AUTOSAR XML (schema 4-2-2)
package /STELLANTIS/EPT/COMSWCs
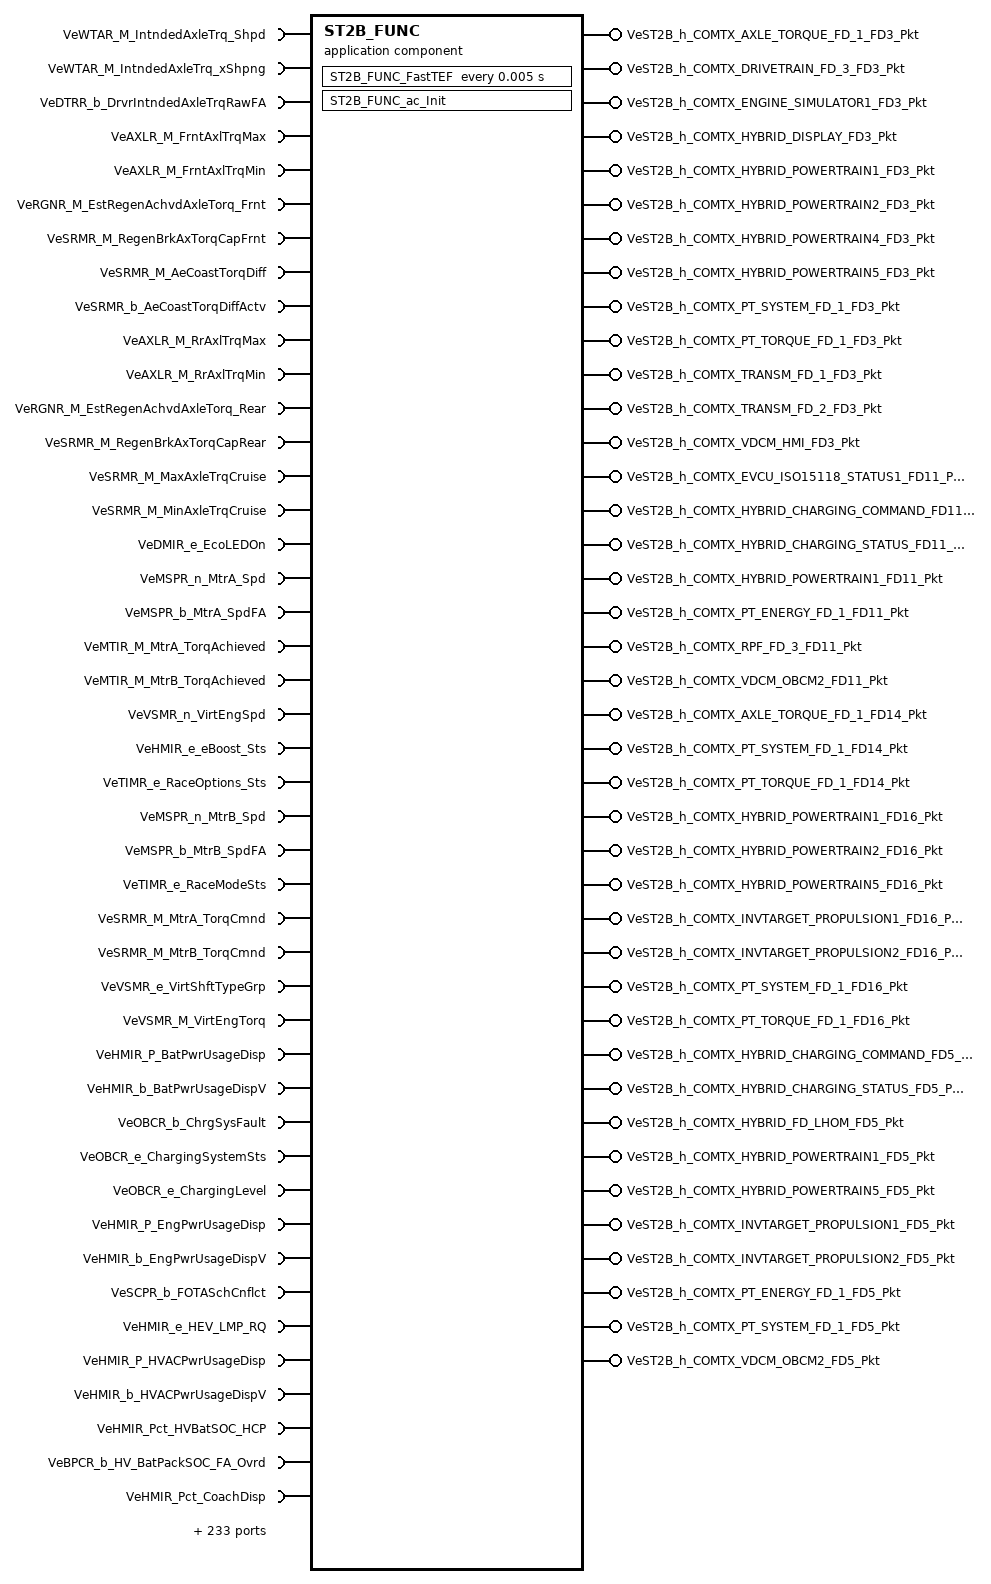
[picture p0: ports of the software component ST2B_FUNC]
  application sw component type ST2B_FUNC
    282 x require port:
      VeWTAR_M_IntndedAxleTrq_Shpd: nonqueued-receiver-com-spec{data-element=Value, init-value=0}, required-interface=VeWTAR_M_IntndedAxleTrq_Shpd
      VeWTAR_M_IntndedAxleTrq_xShpng: nonqueued-receiver-com-spec{data-element=Value, init-value=0}, required-interface=VeWTAR_M_IntndedAxleTrq_xShpng
      VeDTRR_b_DrvrIntndedAxleTrqRawFA: nonqueued-receiver-com-spec{data-element=Value, init-value=0}, required-interface=VeDTRR_b_DrvrIntndedAxleTrqRawFA
      VeAXLR_M_FrntAxlTrqMax: nonqueued-receiver-com-spec{data-element=Value, init-value=0}, required-interface=VeAXLR_M_FrntAxlTrqMax
      VeAXLR_M_FrntAxlTrqMin: nonqueued-receiver-com-spec{data-element=Value, init-value=0}, required-interface=VeAXLR_M_FrntAxlTrqMin
      VeRGNR_M_EstRegenAchvdAxleTorq_Frnt: nonqueued-receiver-com-spec{data-element=Value, init-value=0}, required-interface=VeRGNR_M_EstRegenAchvdAxleTorq_Frnt
      VeSRMR_M_RegenBrkAxTorqCapFrnt: nonqueued-receiver-com-spec{data-element=Value, init-value=0}, required-interface=VeSRMR_M_RegenBrkAxTorqCapFrnt
      VeSRMR_M_AeCoastTorqDiff: nonqueued-receiver-com-spec{data-element=Value, init-value=0}, required-interface=VeSRMR_M_AeCoastTorqDiff
      VeSRMR_b_AeCoastTorqDiffActv: nonqueued-receiver-com-spec{data-element=Value, init-value=0}, required-interface=VeSRMR_b_AeCoastTorqDiffActv
      VeAXLR_M_RrAxlTrqMax: nonqueued-receiver-com-spec{data-element=Value, init-value=0}, required-interface=VeAXLR_M_RrAxlTrqMax
      VeAXLR_M_RrAxlTrqMin: nonqueued-receiver-com-spec{data-element=Value, init-value=0}, required-interface=VeAXLR_M_RrAxlTrqMin
      VeRGNR_M_EstRegenAchvdAxleTorq_Rear: nonqueued-receiver-com-spec{data-element=Value, init-value=0}, required-interface=VeRGNR_M_EstRegenAchvdAxleTorq_Rear
      VeSRMR_M_RegenBrkAxTorqCapRear: nonqueued-receiver-com-spec{data-element=Value, init-value=0}, required-interface=VeSRMR_M_RegenBrkAxTorqCapRear
      VeSRMR_M_MaxAxleTrqCruise: nonqueued-receiver-com-spec{data-element=Value, init-value=0}, required-interface=VeSRMR_M_MaxAxleTrqCruise
      VeSRMR_M_MinAxleTrqCruise: nonqueued-receiver-com-spec{data-element=Value, init-value=0}, required-interface=VeSRMR_M_MinAxleTrqCruise
      VeDMIR_e_EcoLEDOn: variation-point={short-label=vpVeDMIR_e_EcoLEDOn, sw-syscond=1}, nonqueued-receiver-com-spec{data-element=Value, init-value=CeDMDR_e_LEDOff}, required-interface=VeDMIR_e_EcoLEDOn
      VeMSPR_n_MtrA_Spd: variation-point={short-label=vpVeMSPR_n_MtrA_Spd, sw-syscond=1}, nonqueued-receiver-com-spec{data-element=Value, init-value=0}, required-interface=VeMSPR_n_MtrA_Spd
      VeMSPR_b_MtrA_SpdFA: variation-point={short-label=vpVeMSPR_b_MtrA_SpdFA, sw-syscond=1}, nonqueued-receiver-com-spec{data-element=Value, init-value=0}, required-interface=VeMSPR_b_MtrA_SpdFA
      VeMTIR_M_MtrA_TorqAchieved: variation-point={short-label=vpVeMTIR_M_MtrA_TorqAchieved, sw-syscond=1}, nonqueued-receiver-com-spec{data-element=Value, init-value=0}, required-interface=VeMTIR_M_MtrA_TorqAchieved
      VeMTIR_M_MtrB_TorqAchieved: variation-point={short-label=vpVeMTIR_M_MtrB_TorqAchieved, sw-syscond=1}, nonqueued-receiver-com-spec{data-element=Value, init-value=0}, required-interface=VeMTIR_M_MtrB_TorqAchieved
      VeVSMR_n_VirtEngSpd: variation-point={short-label=vpVeVSMR_n_VirtEngSpd, sw-syscond=1}, nonqueued-receiver-com-spec{data-element=Value, init-value=0}, required-interface=VeVSMR_n_VirtEngSpd
      VeHMIR_e_eBoost_Sts: variation-point={short-label=vpVeHMIR_e_eBoost_Sts, sw-syscond=1}, nonqueued-receiver-com-spec{data-element=Value, init-value=CeEBMR_e_eBoostOFF}, required-interface=VeHMIR_e_eBoost_Sts
      VeTIMR_e_RaceOptions_Sts: variation-point={short-label=vpVeTIMR_e_RaceOptions_Sts, sw-syscond=1}, nonqueued-receiver-com-spec{data-element=Value, init-value=CeTIMR_e_NoOptionSelected}, required-interface=VeTIMR_e_RaceOptions_Sts
      VeMSPR_n_MtrB_Spd: variation-point={short-label=vpVeMSPR_n_MtrB_Spd, sw-syscond=1}, nonqueued-receiver-com-spec{data-element=Value, init-value=0}, required-interface=VeMSPR_n_MtrB_Spd
      VeMSPR_b_MtrB_SpdFA: variation-point={short-label=vpVeMSPR_b_MtrB_SpdFA, sw-syscond=1}, nonqueued-receiver-com-spec{data-element=Value, init-value=0}, required-interface=VeMSPR_b_MtrB_SpdFA
      VeTIMR_e_RaceModeSts: variation-point={short-label=vpVeTIMR_e_RaceModeSts, sw-syscond=1}, nonqueued-receiver-com-spec{data-element=Value, init-value=CeTIMR_e_RaceMode_Off}, required-interface=VeTIMR_e_RaceModeSts
      VeSRMR_M_MtrA_TorqCmnd: nonqueued-receiver-com-spec{data-element=Value, init-value=0}, required-interface=VeSRMR_M_MtrA_TorqCmnd
      VeSRMR_M_MtrB_TorqCmnd: nonqueued-receiver-com-spec{data-element=Value, init-value=0}, required-interface=VeSRMR_M_MtrB_TorqCmnd
      VeVSMR_e_VirtShftTypeGrp: variation-point={short-label=vpVeVSMR_e_VirtShftTypeGrp, sw-syscond=1}, nonqueued-receiver-com-spec{data-element=Value, init-value=CeVSMR_e_VST_NoShift}, required-interface=VeVSMR_e_VirtShftTypeGrp
      VeVSMR_M_VirtEngTorq: variation-point={short-label=vpVeVSMR_M_VirtEngTorq, sw-syscond=1}, nonqueued-receiver-com-spec{data-element=Value, init-value=0}, required-interface=VeVSMR_M_VirtEngTorq
      VeHMIR_P_BatPwrUsageDisp: nonqueued-receiver-com-spec{data-element=Value, init-value=0}, required-interface=VeHMIR_P_BatPwrUsageDisp
      VeHMIR_b_BatPwrUsageDispV: nonqueued-receiver-com-spec{data-element=Value, init-value=0}, required-interface=VeHMIR_b_BatPwrUsageDispV
      VeOBCR_b_ChrgSysFault: nonqueued-receiver-com-spec{data-element=Value, init-value=0}, required-interface=VeOBCR_b_ChrgSysFault
      VeOBCR_e_ChargingSystemSts: nonqueued-receiver-com-spec{data-element=Value, init-value=CeOBCR_e_NotCharging}, required-interface=VeOBCR_e_ChargingSystemSts
      VeOBCR_e_ChargingLevel: nonqueued-receiver-com-spec{data-element=Value, init-value=CeOBCR_e_ChargingLvlDefault}, required-interface=VeOBCR_e_ChargingLevel
      VeHMIR_P_EngPwrUsageDisp: nonqueued-receiver-com-spec{data-element=Value, init-value=0}, required-interface=VeHMIR_P_EngPwrUsageDisp
      VeHMIR_b_EngPwrUsageDispV: nonqueued-receiver-com-spec{data-element=Value, init-value=0}, required-interface=VeHMIR_b_EngPwrUsageDispV
      VeSCPR_b_FOTASchCnflct: nonqueued-receiver-com-spec{data-element=Value, init-value=0}, required-interface=VeSCPR_b_FOTASchCnflct
      VeHMIR_e_HEV_LMP_RQ: nonqueued-receiver-com-spec{data-element=Value, init-value=CeHMIR_e_HEV_LMP_OFF}, required-interface=VeHMIR_e_HEV_LMP_RQ
      VeHMIR_P_HVACPwrUsageDisp: nonqueued-receiver-com-spec{data-element=Value, init-value=0}, required-interface=VeHMIR_P_HVACPwrUsageDisp
      VeHMIR_b_HVACPwrUsageDispV: nonqueued-receiver-com-spec{data-element=Value, init-value=0}, required-interface=VeHMIR_b_HVACPwrUsageDispV
      VeHMIR_Pct_HVBatSOC_HCP: nonqueued-receiver-com-spec{data-element=Value, init-value=0}, required-interface=VeHMIR_Pct_HVBatSOC_HCP
      VeBPCR_b_HV_BatPackSOC_FA_Ovrd: nonqueued-receiver-com-spec{data-element=Value, init-value=0}, required-interface=VeBPCR_b_HV_BatPackSOC_FA_Ovrd
      VeHMIR_Pct_CoachDisp: nonqueued-receiver-com-spec{data-element=Value, init-value=0}, required-interface=VeHMIR_Pct_CoachDisp
      VeHMIR_b_CoachDispV: nonqueued-receiver-com-spec{data-element=Value, init-value=0}, required-interface=VeHMIR_b_CoachDispV
      VeHMIR_Pct_OutputPwrDisp: nonqueued-receiver-com-spec{data-element=Value, init-value=0}, required-interface=VeHMIR_Pct_OutputPwrDisp
      VeHMIR_b_OutputPwrDispV: nonqueued-receiver-com-spec{data-element=Value, init-value=0}, required-interface=VeHMIR_b_OutputPwrDispV
      VeOBCR_t_EstTimeofChrg_Lv1: nonqueued-receiver-com-spec{data-element=Value, init-value=0}, required-interface=VeOBCR_t_EstTimeofChrg_Lv1
      VeOBCR_t_EstTimeofChrg_Lv2: nonqueued-receiver-com-spec{data-element=Value, init-value=0}, required-interface=VeOBCR_t_EstTimeofChrg_Lv2
      VeDTRR_e_OPD_HMI: nonqueued-receiver-com-spec{data-element=Value, init-value=CeDTRR_e_Available}, required-interface=VeDTRR_e_OPD_HMI
      VeHMIR_b_Popup_Msg1: variation-point={short-label=vpVeHMIR_b_Popup_Msg1, sw-syscond=1}, nonqueued-receiver-com-spec{data-element=Value, init-value=0}, required-interface=VeHMIR_b_Popup_Msg1
      VeHMIR_b_Popup_Msg10: nonqueued-receiver-com-spec{data-element=Value, init-value=0}, required-interface=VeHMIR_b_Popup_Msg10
      VeHMIR_b_Popup_Msg11: nonqueued-receiver-com-spec{data-element=Value, init-value=0}, required-interface=VeHMIR_b_Popup_Msg11
      VeHMIR_b_Popup_Msg{2..7}: nonqueued-receiver-com-spec{data-element=Value, init-value=0}, required-interface=VeHMIR_b_Popup_Msg{2..7}
      VeSRMR_b_Popup_Msg9: nonqueued-receiver-com-spec{data-element=Value, init-value=0}, required-interface=VeSRMR_b_Popup_Msg9
      VeTIMR_e_RacePrep: variation-point={short-label=vpVeTIMR_e_RacePrep, sw-syscond=1}, nonqueued-receiver-com-spec{data-element=Value, init-value=CeTIMR_e_RacePrep_Off}, required-interface=VeTIMR_e_RacePrep
      VeTAIR_p_HghRfrgtPres: nonqueued-receiver-com-spec{data-element=Value, init-value=0}, required-interface=VeTAIR_p_HghRfrgtPres
      VeTAIR_b_HghRfrgtPres_FA: nonqueued-receiver-com-spec{data-element=Value, init-value=0}, required-interface=VeTAIR_b_HghRfrgtPres_FA
      VeDMIR_e_TellTaleInfo: nonqueued-receiver-com-spec{data-element=Value, init-value=CeDMIR_e_InfoLevel1}, required-interface=VeDMIR_e_TellTaleInfo
      VeHMIR_e_DriveMdstat: nonqueued-receiver-com-spec{data-element=Value, init-value=0}, required-interface=VeHMIR_e_DriveMdstat
      VeHMIR_e_DriveMdstat_PopUpRqst: nonqueued-receiver-com-spec{data-element=Value, init-value=CeDMIR_e_NoDrvMdSt}, required-interface=VeHMIR_e_DriveMdstat_PopUpRqst
      VeHMIR_e_eBoost_Warn: variation-point={short-label=vpVeHMIR_e_eBoost_Warn, sw-syscond=1}, nonqueued-receiver-com-spec{data-element=Value, init-value=CeEBMR_e_DeactivatedESCOff}, required-interface=VeHMIR_e_eBoost_Warn
      VeHMIR_b_DriveReady: nonqueued-receiver-com-spec{data-element=Value, init-value=0}, required-interface=VeHMIR_b_DriveReady
      VeICSR_b_AdvancePrepForIdle: nonqueued-receiver-com-spec{data-element=Value, init-value=0}, required-interface=VeICSR_b_AdvancePrepForIdle
      VeHADR_b_EngActDmpgDsblReq: nonqueued-receiver-com-spec{data-element=Value, init-value=0}, required-interface=VeHADR_b_EngActDmpgDsblReq
      VeTRAR_e_EngCntrlMode: nonqueued-receiver-com-spec{data-element=Value, init-value=CeTRAR_e_TorqueMode}, required-interface=VeTRAR_e_EngCntrlMode
      VeTRAR_M_EngReserveTrqCmnd: nonqueued-receiver-com-spec{data-element=Value, init-value=0}, required-interface=VeTRAR_M_EngReserveTrqCmnd
      VeESSR_b_EngOffAllwdECM: nonqueued-receiver-com-spec{data-element=Value, init-value=0}, required-interface=VeESSR_b_EngOffAllwdECM
      VeGENR_b_HybGenSPDtyCycPtOverAct: nonqueued-receiver-com-spec{data-element=Value, init-value=0}, required-interface=VeGENR_b_HybGenSPDtyCycPtOverAct
      VeESSR_e_EngStrtStpMd: nonqueued-receiver-com-spec{data-element=Value, init-value=CeESSR_e_Stop}, required-interface=VeESSR_e_EngStrtStpMd
      VeTRAR_M_EngTorqCmndImmed: nonqueued-receiver-com-spec{data-element=Value, init-value=0}, required-interface=VeTRAR_M_EngTorqCmndImmed
      VeTRAR_M_HybCmndEngTorqPrdtd: nonqueued-receiver-com-spec{data-element=Value, init-value=0}, required-interface=VeTRAR_M_HybCmndEngTorqPrdtd
      VeTRAR_e_HybCmndEngTorqRespTyp: nonqueued-receiver-com-spec{data-element=Value, init-value=CeTRAR_e_Inactive}, required-interface=VeTRAR_e_HybCmndEngTorqRespTyp
      VeSTRR_b_HybCrnkAbrtd: nonqueued-receiver-com-spec{data-element=Value, init-value=0}, required-interface=VeSTRR_b_HybCrnkAbrtd
      VeTRAR_b_EngDFCOReq: nonqueued-receiver-com-spec{data-element=Value, init-value=0}, required-interface=VeTRAR_b_EngDFCOReq
      VeSRAR_b_CAN_HybFeedback_ECM: nonqueued-receiver-com-spec{data-element=Value, init-value=0}, required-interface=VeSRAR_b_CAN_HybFeedback_ECM
      VeHSER_e_RngStOnCAN: nonqueued-receiver-com-spec{data-element=Value, init-value=CeHSER_e_Init}, required-interface=VeHSER_e_RngStOnCAN
      VeSRAR_b_HCP_Remedial_Stop: variation-point={short-label=vpVeSRAR_b_HCP_Remedial_Stop, sw-syscond=1}, nonqueued-receiver-com-spec{data-element=Value, init-value=0}, required-interface=VeSRAR_b_HCP_Remedial_Stop
      VeTISR_n_InputSpeedRaw: nonqueued-receiver-com-spec{data-element=Value, init-value=0}, required-interface=VeTISR_n_InputSpeedRaw
      VeTISR_b_InputSpeedFA: nonqueued-receiver-com-spec{data-element=Value, init-value=0}, required-interface=VeTISR_b_InputSpeedFA
      VeGENR_b_LowVoltSysFldToECM: nonqueued-receiver-com-spec{data-element=Value, init-value=0}, required-interface=VeGENR_b_LowVoltSysFldToECM
      VeHPMR_b_PropSysActv: nonqueued-receiver-com-spec{data-element=Value, init-value=0}, required-interface=VeHPMR_b_PropSysActv
      VeHSER_n_InputSpeedProfile: nonqueued-receiver-com-spec{data-element=Value, init-value=0}, required-interface=VeHSER_n_InputSpeedProfile
      VeOHSR_n_IdleSpeed_Target: nonqueued-receiver-com-spec{data-element=Value, init-value=0}, required-interface=VeOHSR_n_IdleSpeed_Target
      VeTRNR_b_PwrTrnIdlSpdActvSts: nonqueued-receiver-com-spec{data-element=Value, init-value=0}, required-interface=VeTRNR_b_PwrTrnIdlSpdActvSts
      VeTMDR_e_Arb_TrrnMd: variation-point={short-label=vpVeTMDR_e_Arb_TrrnMd, sw-syscond=1}, nonqueued-receiver-com-spec{data-element=Value, init-value=0}, required-interface=VeTMDR_e_Arb_TrrnMd
      VeBACR_r_ElecPwrTorq_PedalFact: nonqueued-receiver-com-spec{data-element=Value, init-value=0}, required-interface=VeBACR_r_ElecPwrTorq_PedalFact
      VeSRAR_n_HCPMaxEngRPM: nonqueued-receiver-com-spec{data-element=Value, init-value=0}, required-interface=VeSRAR_n_HCPMaxEngRPM
      VeESSR_b_HCP_StopStart_Fault: nonqueued-receiver-com-spec{data-element=Value, init-value=0}, required-interface=VeESSR_b_HCP_StopStart_Fault
      VeSRAR_b_HybPwrtrnRdcdPerfCmnd: nonqueued-receiver-com-spec{data-element=Value, init-value=0}, required-interface=VeSRAR_b_HybPwrtrnRdcdPerfCmnd
      VeCOMR_b_Random3: nonqueued-receiver-com-spec{data-element=Value, init-value=0}, required-interface=VeCOMR_b_Random3
      VeTAIR_Pct_AGS2_CurrPos: nonqueued-receiver-com-spec{data-element=Value, init-value=0}, required-interface=VeTAIR_Pct_AGS2_CurrPos
      VeTAIR_b_AGS2_CurrPosFA: nonqueued-receiver-com-spec{data-element=Value, init-value=0}, required-interface=VeTAIR_b_AGS2_CurrPosFA
      VeTAIR_Pct_AGS_CurrPos: nonqueued-receiver-com-spec{data-element=Value, init-value=0}, required-interface=VeTAIR_Pct_AGS_CurrPos
      VeTAIR_b_AGS_CurrPosFA: nonqueued-receiver-com-spec{data-element=Value, init-value=0}, required-interface=VeTAIR_b_AGS_CurrPosFA
      VeHMIR_b_HEV_EVT_MD: nonqueued-receiver-com-spec{data-element=Value, init-value=0}, required-interface=VeHMIR_b_HEV_EVT_MD
      VeTIMR_e_LaunchIntensity: variation-point={short-label=vpVeTIMR_e_LaunchIntensity, sw-syscond=1}, nonqueued-receiver-com-spec{data-element=Value, init-value=CeTIMR_e_Max}, required-interface=VeTIMR_e_LaunchIntensity
      VeHMIR_P_MtrAPwrUsageDisp: variation-point={short-label=vpVeHMIR_P_MtrAPwrUsageDisp, sw-syscond=1}, nonqueued-receiver-com-spec{data-element=Value, init-value=0}, required-interface=VeHMIR_P_MtrAPwrUsageDisp
      VeHMIR_P_MtrAPwrUsageDispV: variation-point={short-label=vpVeHMIR_P_MtrAPwrUsageDispV, sw-syscond=1}, nonqueued-receiver-com-spec{data-element=Value, init-value=0}, required-interface=VeHMIR_P_MtrAPwrUsageDispV
      VeHMIR_P_MtrBPwrUsageDisp: nonqueued-receiver-com-spec{data-element=Value, init-value=0}, required-interface=VeHMIR_P_MtrBPwrUsageDisp
      VeHMIR_P_MtrBPwrUsageDispV: nonqueued-receiver-com-spec{data-element=Value, init-value=0}, required-interface=VeHMIR_P_MtrBPwrUsageDispV
      VeHMIR_P_MtrPwrUsageDisp: nonqueued-receiver-com-spec{data-element=Value, init-value=0}, required-interface=VeHMIR_P_MtrPwrUsageDisp
      VeHMIR_b_MtrPwrUsageDispV: nonqueued-receiver-com-spec{data-element=Value, init-value=0}, required-interface=VeHMIR_b_MtrPwrUsageDispV
      VeSRMR_e_AHH_ApplyRelease_Req: nonqueued-receiver-com-spec{data-element=Value, init-value=0}, required-interface=VeSRMR_e_AHH_ApplyRelease_Req
      VeSRMR_b_AHH_ModifyAccel_Req: nonqueued-receiver-com-spec{data-element=Value, init-value=0}, required-interface=VeSRMR_b_AHH_ModifyAccel_Req
      VeTRGR_e_AutoPosCorrMdReq: nonqueued-receiver-com-spec{data-element=Value, init-value=CeTRGR_e_AutoPosCorrMd_Off}, required-interface=VeTRGR_e_AutoPosCorrMdReq
      VeADCR_e_AWDSysStat: nonqueued-receiver-com-spec{data-element=Value, init-value=CeADCR_e_TwoWheelDrive}, required-interface=VeADCR_e_AWDSysStat
      VeGENR_b_SrvcBattReChrgFlSts: nonqueued-receiver-com-spec{data-element=Value, init-value=0}, required-interface=VeGENR_b_SrvcBattReChrgFlSts
      VePLTR_pmbar_AmbientAirPrs: nonqueued-receiver-com-spec{data-element=Value, init-value=0}, required-interface=VePLTR_pmbar_AmbientAirPrs
      VeCCTR_v_CcCntrlSpd_Cluster_KPH: nonqueued-receiver-com-spec{data-element=Value, init-value=0}, required-interface=VeCCTR_v_CcCntrlSpd_Cluster_KPH
      VeCCTR_v_CcCntrlSpd_Cluster_MPH: nonqueued-receiver-com-spec{data-element=Value, init-value=0}, required-interface=VeCCTR_v_CcCntrlSpd_Cluster_MPH
      VeTRGR_b_CrankEnabled: nonqueued-receiver-com-spec{data-element=Value, init-value=0}, required-interface=VeTRGR_b_CrankEnabled
      VeCCTR_b_CcLampSts: nonqueued-receiver-com-spec{data-element=Value, init-value=0}, required-interface=VeCCTR_b_CcLampSts
      VeCCTR_b_CcEngaged: nonqueued-receiver-com-spec{data-element=Value, init-value=0}, required-interface=VeCCTR_b_CcEngaged
      VeTIMR_e_CustomDrvMdSts: nonqueued-receiver-com-spec{data-element=Value, init-value=CeTMDR_e_NotDefine}, required-interface=VeTIMR_e_CustomDrvMdSts
      VeHMIR_b_DrvAwayAlt: nonqueued-receiver-com-spec{data-element=Value, init-value=0}, required-interface=VeHMIR_b_DrvAwayAlt
      VeHMIR_b_DrvAwayIn: nonqueued-receiver-com-spec{data-element=Value, init-value=0}, required-interface=VeHMIR_b_DrvAwayIn
      VeTRGR_b_AutoPark_DAI: nonqueued-receiver-com-spec{data-element=Value, init-value=0}, required-interface=VeTRGR_b_AutoPark_DAI
      VeSRMR_b_Lv2AccelPdlPosFlt: nonqueued-receiver-com-spec{data-element=Value, init-value=0}, required-interface=VeSRMR_b_Lv2AccelPdlPosFlt
      VeDTRR_Pct_AccelPdlVirtActPosn: nonqueued-receiver-com-spec{data-element=Value, init-value=0}, required-interface=VeDTRR_Pct_AccelPdlVirtActPosn
      VeTRGR_e_CurrentGrForDisp: nonqueued-receiver-com-spec{data-element=Value, init-value=0}, required-interface=VeTRGR_e_CurrentGrForDisp
      VeTRGR_e_CurrentGear: nonqueued-receiver-com-spec{data-element=Value, init-value=0}, required-interface=VeTRGR_e_CurrentGear
      VeTRGR_b_GearIndicationSts: nonqueued-receiver-com-spec{data-element=Value, init-value=0}, required-interface=VeTRGR_b_GearIndicationSts
      VeASLR_b_ISASts: nonqueued-receiver-com-spec{data-element=Value, init-value=0}, required-interface=VeASLR_b_ISASts
      VeDMIR_e_PaddleModeSts: nonqueued-receiver-com-spec{data-element=Value, init-value=CeDMIR_e_None}, required-interface=VeDMIR_e_PaddleModeSts
      VeTRGR_b_ParkingFailSts: nonqueued-receiver-com-spec{data-element=Value, init-value=0}, required-interface=VeTRGR_b_ParkingFailSts
      VeTRGR_b_ParkingSts: nonqueued-receiver-com-spec{data-element=Value, init-value=0}, required-interface=VeTRGR_b_ParkingSts
      VeSRMR_Pct_Lv2AccelPdlPos: nonqueued-receiver-com-spec{data-element=Value, init-value=0}, required-interface=VeSRMR_Pct_Lv2AccelPdlPos
      VeTRGR_b_ADAS_Allowed: nonqueued-receiver-com-spec{data-element=Value, init-value=0}, required-interface=VeTRGR_b_ADAS_Allowed
      VeTRGR_b_R_Shift_Block: nonqueued-receiver-com-spec{data-element=Value, init-value=0}, required-interface=VeTRGR_b_R_Shift_Block
      VeAPSR_U_RawPVS1: nonqueued-receiver-com-spec{data-element=Value, init-value=0}, required-interface=VeAPSR_U_RawPVS1
      VeAPSR_U_RawPVS2: nonqueued-receiver-com-spec{data-element=Value, init-value=0}, required-interface=VeAPSR_U_RawPVS2
      VeTRGR_e_SecureIdle_HMI: nonqueued-receiver-com-spec{data-element=Value, init-value=CeTRGR_e_SecureIdleHMI_Default}, required-interface=VeTRGR_e_SecureIdle_HMI
      VeTRGR_e_SecureIdleSts: nonqueued-receiver-com-spec{data-element=Value, init-value=0}, required-interface=VeTRGR_e_SecureIdleSts
      VeTIMR_b_Selector_Sys_Fail_Sts: nonqueued-receiver-com-spec{data-element=Value, init-value=0}, required-interface=VeTIMR_b_Selector_Sys_Fail_Sts
      VeTRGR_b_ShifterLocked: nonqueued-receiver-com-spec{data-element=Value, init-value=0}, required-interface=VeTRGR_b_ShifterLocked
      VeSRMR_e_PRNDLReq: nonqueued-receiver-com-spec{data-element=Value, init-value=0}, required-interface=VeSRMR_e_PRNDLReq
      VeASLR_e_SpdLmtSts: nonqueued-receiver-com-spec{data-element=Value, init-value=0}, required-interface=VeASLR_e_SpdLmtSts
      VeTRGR_e_TargetGear: nonqueued-receiver-com-spec{data-element=Value, init-value=0}, required-interface=VeTRGR_e_TargetGear
      VeHMIR_e_TerrainModeDesiredStat: nonqueued-receiver-com-spec{data-element=Value, init-value=CeHMIR_e_Auto}, required-interface=VeHMIR_e_TerrainModeDesiredStat
      VeTIMR_e_CustomScreenRqst: variation-point={short-label=vpVeTIMR_e_CustomScreenRqst, sw-syscond=1}, nonqueued-receiver-com-spec{data-element=Value, init-value=CeTIMR_e_NotActivated}, required-interface=VeTIMR_e_CustomScreenRqst
      VeHMIR_e_TerrainModeStat: nonqueued-receiver-com-spec{data-element=Value, init-value=CeHMIR_e_AutoStat}, required-interface=VeHMIR_e_TerrainModeStat
      VeHMIR_e_TerrainHMIRq: nonqueued-receiver-com-spec{data-element=Value, init-value=CeHMIR_e_No_Request}, required-interface=VeHMIR_e_TerrainHMIRq
      VeTRGR_b_TransmissionFailSts: nonqueued-receiver-com-spec{data-element=Value, init-value=0}, required-interface=VeTRGR_b_TransmissionFailSts
      VeHMIR_e_TransWarn2: nonqueued-receiver-com-spec{data-element=Value, init-value=CeHMIR_e_Warn2_None}, required-interface=VeHMIR_e_TransWarn2
      VeDMDR_e_TurtleMdSts: nonqueued-receiver-com-spec{data-element=Value, init-value=CeDMDR_e_No_Turtle_Mode}, required-interface=VeDMDR_e_TurtleMdSts
      VeASLR_e_DrvMdOvrrdKickdownSt: nonqueued-receiver-com-spec{data-element=Value, init-value=0}, required-interface=VeASLR_e_DrvMdOvrrdKickdownSt
      VeSRMR_e_EPB_Hold_Req: nonqueued-receiver-com-spec{data-element=Value, init-value=0}, required-interface=VeSRMR_e_EPB_Hold_Req
      VeADCR_i_WEDAxleStat_CAN: nonqueued-receiver-com-spec{data-element=Value, init-value=0}, required-interface=VeADCR_i_WEDAxleStat_CAN
      VeAPSR_b_Lv1PvBrkActive: nonqueued-receiver-com-spec{data-element=Value, init-value=0}, required-interface=VeAPSR_b_Lv1PvBrkActive
      VeDTRR_b_EngTrqEnblRqDAS: nonqueued-receiver-com-spec{data-element=Value, init-value=0}, required-interface=VeDTRR_b_EngTrqEnblRqDAS
      VeDTRR_b_PtcCcDriverOverride: nonqueued-receiver-com-spec{data-element=Value, init-value=0}, required-interface=VeDTRR_b_PtcCcDriverOverride
      VeSCCR_b_ESCTrqEnblRq_Allowed: nonqueued-receiver-com-spec{data-element=Value, init-value=0}, required-interface=VeSCCR_b_ESCTrqEnblRq_Allowed
      VeSRMR_M_SplitFrntTrqReq: nonqueued-receiver-com-spec{data-element=Value, init-value=0}, required-interface=VeSRMR_M_SplitFrntTrqReq
      VeAXLR_M_SplitFrntTrqReq: nonqueued-receiver-com-spec{data-element=Value, init-value=0}, required-interface=VeAXLR_M_SplitFrntTrqReq
      VeSRMR_M_SplitRearTrqReq: nonqueued-receiver-com-spec{data-element=Value, init-value=0}, required-interface=VeSRMR_M_SplitRearTrqReq
      VeAXLR_M_SplitRrAxlTrqReq: nonqueued-receiver-com-spec{data-element=Value, init-value=0}, required-interface=VeAXLR_M_SplitRrAxlTrqReq
      VeTTQR_M_LoadFrontOptExp: variation-point={short-label=vpVeTTQR_M_LoadFrontOptExp, sw-syscond=1}, nonqueued-receiver-com-spec{data-element=Value, init-value=0}, required-interface=VeTTQR_M_LoadFrontOptExp
      VeTTQR_M_LoadTorqFront_Max: nonqueued-receiver-com-spec{data-element=Value, init-value=0}, required-interface=VeTTQR_M_LoadTorqFront_Max
      VeTTQR_M_SumTrqMinPwrTrn: nonqueued-receiver-com-spec{data-element=Value, init-value=0}, required-interface=VeTTQR_M_SumTrqMinPwrTrn
      VeTTQR_M_SumTrqStatic: nonqueued-receiver-com-spec{data-element=Value, init-value=0}, required-interface=VeTTQR_M_SumTrqStatic
      VeSRMR_M_ActualAxleTrq: nonqueued-receiver-com-spec{data-element=Value, init-value=0}, required-interface=VeSRMR_M_ActualAxleTrq
      VeSRMR_b_VehStndStillReq_OPD: nonqueued-receiver-com-spec{data-element=Value, init-value=0}, required-interface=VeSRMR_b_VehStndStillReq_OPD
      VeHMIR_b_ThrmlRnAway_Lmp: nonqueued-receiver-com-spec{data-element=Value, init-value=0}, required-interface=VeHMIR_b_ThrmlRnAway_Lmp
      VeOBCR_t_EstTimeDCFastChrg_80: nonqueued-receiver-com-spec{data-element=Value, init-value=0}, required-interface=VeOBCR_t_EstTimeDCFastChrg_80
      VeOBCR_t_EstTimeDCFastChrg_100: nonqueued-receiver-com-spec{data-element=Value, init-value=0}, required-interface=VeOBCR_t_EstTimeDCFastChrg_100
      VeERER_l_EstRange: nonqueued-receiver-com-spec{data-element=Value, init-value=0}, required-interface=VeERER_l_EstRange
      VeERER_b_EstRange_SNA: nonqueued-receiver-com-spec{data-element=Value, init-value=0}, required-interface=VeERER_b_EstRange_SNA
      VeHMIR_Pct_EstSOCDisplay: nonqueued-receiver-com-spec{data-element=Value, init-value=0}, required-interface=VeHMIR_Pct_EstSOCDisplay
      VeERER_l_EstRange_ChrgStpTime: nonqueued-receiver-com-spec{data-element=Value, init-value=0}, required-interface=VeERER_l_EstRange_ChrgStpTime
      VeHMIR_e_VDCM_PopUpChrgPrtMis: nonqueued-receiver-com-spec{data-element=Value, init-value=CeHMIR_e_Not_Availabl}, required-interface=VeHMIR_e_VDCM_PopUpChrgPrtMis
      VeSSDR_b_DrvNotAllwdTPChckKeepPlugIn: nonqueued-receiver-com-spec{data-element=Value, init-value=0}, required-interface=VeSSDR_b_DrvNotAllwdTPChckKeepPlugIn
      VeOBCR_I_EVMax_I_Limit: nonqueued-receiver-com-spec{data-element=Value, init-value=0}, required-interface=VeOBCR_I_EVMax_I_Limit
      VeOBCR_U_EVMax_V_Limit: nonqueued-receiver-com-spec{data-element=Value, init-value=0}, required-interface=VeOBCR_U_EVMax_V_Limit
      VeOBCR_e_ChargeProgress: nonqueued-receiver-com-spec{data-element=Value, init-value=CeOBCR_e_No_Request}, required-interface=VeOBCR_e_ChargeProgress
      VeOBCR_E_EVEnergyCapacity: nonqueued-receiver-com-spec{data-element=Value, init-value=0}, required-interface=VeOBCR_E_EVEnergyCapacity
      VeOBCR_E_EVEnergyRequest: nonqueued-receiver-com-spec{data-element=Value, init-value=0}, required-interface=VeOBCR_E_EVEnergyRequest
      VeOBCR_e_HCP_EVErrorCode: nonqueued-receiver-com-spec{data-element=Value, init-value=0}, required-interface=VeOBCR_e_HCP_EVErrorCode
      VeOBCR_t_RemTimeToBulkSOC: nonqueued-receiver-com-spec{data-element=Value, init-value=0}, required-interface=VeOBCR_t_RemTimeToBulkSOC
      VeOBCR_t_RemTimeToFullSOC: nonqueued-receiver-com-spec{data-element=Value, init-value=0}, required-interface=VeOBCR_t_RemTimeToFullSOC
      VeOBCR_k_MaxEntriesSASScheduleTuple: nonqueued-receiver-com-spec{data-element=Value, init-value=0}, required-interface=VeOBCR_k_MaxEntriesSASScheduleTuple
      VeOBCR_e_Protocol_Priority{1..3}: nonqueued-receiver-com-spec{data-element=Value, init-value=CeOBCR_e_No_Protocol}, required-interface=VeOBCR_e_Protocol_Priority{1..3}
      VeOBCR_I_MaxAllowableCrntAC: nonqueued-receiver-com-spec{data-element=Value, init-value=0}, required-interface=VeOBCR_I_MaxAllowableCrntAC
      VeOBCR_b_EnblChrg: nonqueued-receiver-com-spec{data-element=Value, init-value=0}, required-interface=VeOBCR_b_EnblChrg
      VeOBCR_I_ChrgCrntReqDelta: nonqueued-receiver-com-spec{data-element=Value, init-value=0}, required-interface=VeOBCR_I_ChrgCrntReqDelta
      VeOBCR_I_MaxAllowableCrntBatt: nonqueued-receiver-com-spec{data-element=Value, init-value=0}, required-interface=VeOBCR_I_MaxAllowableCrntBatt
      VeTHMR_e_HV_Bat_CltLvlLo: nonqueued-receiver-com-spec{data-element=Value, init-value=CeBRDR_e_BatCltLvlNotLo}, required-interface=VeTHMR_e_HV_Bat_CltLvlLo
      VeOBCR_U_MaxAllowableBattVolt: nonqueued-receiver-com-spec{data-element=Value, init-value=0}, required-interface=VeOBCR_U_MaxAllowableBattVolt
      VeOBCR_U_MinAllowableBattVolt: nonqueued-receiver-com-spec{data-element=Value, init-value=0}, required-interface=VeOBCR_U_MinAllowableBattVolt
      VeOBCR_b_CloseS2Cntctr: nonqueued-receiver-com-spec{data-element=Value, init-value=0}, required-interface=VeOBCR_b_CloseS2Cntctr
      VeVTLR_I_MaxCurrAlwd_IDCM: nonqueued-receiver-com-spec{data-element=Value, init-value=0}, required-interface=VeVTLR_I_MaxCurrAlwd_IDCM
      VeOBCR_e_ChrgrTrsfMethodReq: nonqueued-receiver-com-spec{data-element=Value, init-value=CeOBCR_e_Current}, required-interface=VeOBCR_e_ChrgrTrsfMethodReq
      VeOBCR_e_ChrgrModeReq: nonqueued-receiver-com-spec{data-element=Value, init-value=CeOBCR_e_Idle_OBCMdRq}, required-interface=VeOBCR_e_ChrgrModeReq
      VeOBCR_b_HCP_SessionStpCmd: nonqueued-receiver-com-spec{data-element=Value, init-value=0}, required-interface=VeOBCR_b_HCP_SessionStpCmd
      VeOBCR_U_ChrgVltReqDelta: nonqueued-receiver-com-spec{data-element=Value, init-value=0}, required-interface=VeOBCR_U_ChrgVltReqDelta
      VeOBCR_b_ChrgSysFaultBPCM: nonqueued-receiver-com-spec{data-element=Value, init-value=0}, required-interface=VeOBCR_b_ChrgSysFaultBPCM
      VeOBCR_k_ChrgSysFault_Reason: nonqueued-receiver-com-spec{data-element=Value, init-value=0}, required-interface=VeOBCR_k_ChrgSysFault_Reason
      VeOBCR_b_PluggedIn: nonqueued-receiver-com-spec{data-element=Value, init-value=0}, required-interface=VeOBCR_b_PluggedIn
      VeBPCR_I_HV_BatCurr: nonqueued-receiver-com-spec{data-element=Value, init-value=0}, required-interface=VeBPCR_I_HV_BatCurr
      VeBPCR_b_HV_BatCurrFA: nonqueued-receiver-com-spec{data-element=Value, init-value=0}, required-interface=VeBPCR_b_HV_BatCurrFA
      VeBPCR_U_HV_BatVolt: nonqueued-receiver-com-spec{data-element=Value, init-value=0}, required-interface=VeBPCR_U_HV_BatVolt
      VeBPCR_b_HV_BatVoltFA: nonqueued-receiver-com-spec{data-element=Value, init-value=0}, required-interface=VeBPCR_b_HV_BatVoltFA
      VeGENR_e_stModeReq: nonqueued-receiver-com-spec{data-element=Value, init-value=CeGENR_e_Default}, required-interface=VeGENR_e_stModeReq
      VeGENR_I_APMIdcHvSetP: nonqueued-receiver-com-spec{data-element=Value, init-value=0}, required-interface=VeGENR_I_APMIdcHvSetP
      VeGENR_b_APMIdcHvSetPFA: nonqueued-receiver-com-spec{data-element=Value, init-value=0}, required-interface=VeGENR_b_APMIdcHvSetPFA
      VeGENR_I_APM_IdcLvSetP: nonqueued-receiver-com-spec{data-element=Value, init-value=0}, required-interface=VeGENR_I_APM_IdcLvSetP
      VeGENR_U_IBS_BattVoltOut: nonqueued-receiver-com-spec{data-element=Value, init-value=0}, required-interface=VeGENR_U_IBS_BattVoltOut
      VeGENR_U_SetPVoltRq: nonqueued-receiver-com-spec{data-element=Value, init-value=0}, required-interface=VeGENR_U_SetPVoltRq
      VeGENR_b_SetPVoltRqFA: nonqueued-receiver-com-spec{data-element=Value, init-value=0}, required-interface=VeGENR_b_SetPVoltRqFA
      VeOBCR_e_DC_CntctrCmd: nonqueued-receiver-com-spec{data-element=Value, init-value=CeOBCR_e_DCCntctr_Open}, required-interface=VeOBCR_e_DC_CntctrCmd
      VeOBCR_b_DC_Isolation_Cmd: nonqueued-receiver-com-spec{data-element=Value, init-value=0}, required-interface=VeOBCR_b_DC_Isolation_Cmd
      VeHVTR_U_HV_Volt: nonqueued-receiver-com-spec{data-element=Value, init-value=0}, required-interface=VeHVTR_U_HV_Volt
      VeHVTR_b_HV_VoltFA: nonqueued-receiver-com-spec{data-element=Value, init-value=0}, required-interface=VeHVTR_b_HV_VoltFA
      VeSRMR_e_MainHighVltCntctrCmd: nonqueued-receiver-com-spec{data-element=Value, init-value=0}, required-interface=VeSRMR_e_MainHighVltCntctrCmd
      VeOBCR_b_DCChrgInitialization: nonqueued-receiver-com-spec{data-element=Value, init-value=0}, required-interface=VeOBCR_b_DCChrgInitialization
      VeOBCR_e_DC_ChrgTypeCmd: nonqueued-receiver-com-spec{data-element=Value, init-value=CeOBCR_e_DC_ChrgType_Null}, required-interface=VeOBCR_e_DC_ChrgTypeCmd
      VeHPMR_b_EVCURespAuxLoadOff: nonqueued-receiver-com-spec{data-element=Value, init-value=0}, required-interface=VeHPMR_b_EVCURespAuxLoadOff
      VeVTLR_b_ACFreqCmd: nonqueued-receiver-com-spec{data-element=Value, init-value=0}, required-interface=VeVTLR_b_ACFreqCmd
      VeVTLR_I_MaxCurrAlwd_PPIM: nonqueued-receiver-com-spec{data-element=Value, init-value=0}, required-interface=VeVTLR_I_MaxCurrAlwd_PPIM
      VeVTLR_e_PPIM_MdRq: nonqueued-receiver-com-spec{data-element=Value, init-value=CeVTLR_e_Idle}, required-interface=VeVTLR_e_PPIM_MdRq
      VeOBCR_b_CPIM_Error: nonqueued-receiver-com-spec{data-element=Value, init-value=0}, required-interface=VeOBCR_b_CPIM_Error
      VeOBCR_b_CPIM_OT: nonqueued-receiver-com-spec{data-element=Value, init-value=0}, required-interface=VeOBCR_b_CPIM_OT
      VeOBCR_e_HCP_DC_Retry: nonqueued-receiver-com-spec{data-element=Value, init-value=CeOBCR_e_No_Retry_Command}, required-interface=VeOBCR_e_HCP_DC_Retry
      VeOBCR_e_SelectAppProtocol: nonqueued-receiver-com-spec{data-element=Value, init-value=CeOBCR_e_DIN}, required-interface=VeOBCR_e_SelectAppProtocol
      VeOBCR_b_SelectSecProtocol: nonqueued-receiver-com-spec{data-element=Value, init-value=0}, required-interface=VeOBCR_b_SelectSecProtocol
      VeOBCR_Pct_BattFullSOC: nonqueued-receiver-com-spec{data-element=Value, init-value=0}, required-interface=VeOBCR_Pct_BattFullSOC
      VeOBCR_b_BattOverVolt: nonqueued-receiver-com-spec{data-element=Value, init-value=0}, required-interface=VeOBCR_b_BattOverVolt
      VeOBCR_e_BattTemp_OOR: nonqueued-receiver-com-spec{data-element=Value, init-value=CeOBCR_e_BattTempStat_Normal}, required-interface=VeOBCR_e_BattTemp_OOR
      VeOBCR_b_BattUnderVolt: nonqueued-receiver-com-spec{data-element=Value, init-value=0}, required-interface=VeOBCR_b_BattUnderVolt
      VeOBCR_e_CellVolt_OOR: nonqueued-receiver-com-spec{data-element=Value, init-value=CeOBCR_e_CellVoltStat_Normal}, required-interface=VeOBCR_e_CellVolt_OOR
      VeOBCR_e_ChrgCurr_OOR: nonqueued-receiver-com-spec{data-element=Value, init-value=CeOBCR_e_ChrgCurrStat_Normal}, required-interface=VeOBCR_e_ChrgCurr_OOR
      VeOBCR_e_SOC_OOR: nonqueued-receiver-com-spec{data-element=Value, init-value=CeOBCR_e_BattSOCStat_Normal}, required-interface=VeOBCR_e_SOC_OOR
      VeOBCR_b_WeldChkComplete: nonqueued-receiver-com-spec{data-element=Value, init-value=0}, required-interface=VeOBCR_b_WeldChkComplete
      VeSRMR_M_SnsdEng_Flt: nonqueued-receiver-com-spec{data-element=Value, init-value=0}, required-interface=VeSRMR_M_SnsdEng_Flt
      VeSRMR_b_SnsdTi_notVld: nonqueued-receiver-com-spec{data-element=Value, init-value=0}, required-interface=VeSRMR_b_SnsdTi_notVld
      VeHSER_e_RngStToPropulsionMode: nonqueued-receiver-com-spec{data-element=Value, init-value=CeHSER_e_PropModeSNA}, required-interface=VeHSER_e_RngStToPropulsionMode
      VeHTDR_f_MtrA_AEMDFc_Hi: nonqueued-receiver-com-spec{data-element=Value, init-value=0}, required-interface=VeHTDR_f_MtrA_AEMDFc_Hi
      VeHTDR_f_MtrB_AEMDFc_Hi: nonqueued-receiver-com-spec{data-element=Value, init-value=0}, required-interface=VeHTDR_f_MtrB_AEMDFc_Hi
      VeHTDR_f_MtrA_AEMDFc_Lo: nonqueued-receiver-com-spec{data-element=Value, init-value=0}, required-interface=VeHTDR_f_MtrA_AEMDFc_Lo
      VeHTDR_f_MtrB_AEMDFc_Lo: nonqueued-receiver-com-spec{data-element=Value, init-value=0}, required-interface=VeHTDR_f_MtrB_AEMDFc_Lo
      VeHTDR_M_MtrA_AEMDPosTrqOffst: variation-point={short-label=vpVeHTDR_M_MtrA_AEMDPosTrqOffst, sw-syscond=1}, nonqueued-receiver-com-spec{data-element=Value, init-value=0}, required-interface=VeHTDR_M_MtrA_AEMDPosTrqOffst
      VeHTDR_M_MtrB_AEMDPosTrqOffst: nonqueued-receiver-com-spec{data-element=Value, init-value=0}, required-interface=VeHTDR_M_MtrB_AEMDPosTrqOffst
      VeHTDR_M_MtrA_AEMDNegTrqOffst: variation-point={short-label=vpVeHTDR_M_MtrA_AEMDNegTrqOffst, sw-syscond=1}, nonqueued-receiver-com-spec{data-element=Value, init-value=0}, required-interface=VeHTDR_M_MtrA_AEMDNegTrqOffst
      VeHTDR_M_MtrB_AEMDNegTrqOffst: nonqueued-receiver-com-spec{data-element=Value, init-value=0}, required-interface=VeHTDR_M_MtrB_AEMDNegTrqOffst
      VeHTDR_scl_MtrA_AEMDPGainScl: variation-point={short-label=vpVeHTDR_scl_MtrA_AEMDPGainScl, sw-syscond=1}, nonqueued-receiver-com-spec{data-element=Value, init-value=0}, required-interface=VeHTDR_scl_MtrA_AEMDPGainScl
      VeHTDR_scl_MtrB_AEMDPGainScl: nonqueued-receiver-com-spec{data-element=Value, init-value=0}, required-interface=VeHTDR_scl_MtrB_AEMDPGainScl
      VeBPCR_e_HV_BatCntctrStat: nonqueued-receiver-com-spec{data-element=Value, init-value=CeHVTR_e_Open}, required-interface=VeBPCR_e_HV_BatCntctrStat
      VePMDR_e_PowerModeRaw: nonqueued-receiver-com-spec{data-element=Value, init-value=CePMDR_e_PowerMode_Off}, required-interface=VePMDR_e_PowerModeRaw
      VeSRMR_e_MtrA_MdCmnd: nonqueued-receiver-com-spec{data-element=Value, init-value=CeHTDR_e_DsblNoSwitch}, required-interface=VeSRMR_e_MtrA_MdCmnd
      VeSRMR_e_MtrB_MdCmnd: nonqueued-receiver-com-spec{data-element=Value, init-value=CeHTDR_e_DsblNoSwitch}, required-interface=VeSRMR_e_MtrB_MdCmnd
      VeHTDR_b_MtrA_ZeroTrq_Rqst: variation-point={short-label=vpVeHTDR_b_MtrA_ZeroTrq_Rqst, sw-syscond=1}, nonqueued-receiver-com-spec{data-element=Value, init-value=0}, required-interface=VeHTDR_b_MtrA_ZeroTrq_Rqst
      VeHTDR_b_MtrB_ZeroTrq_Rqst: nonqueued-receiver-com-spec{data-element=Value, init-value=0}, required-interface=VeHTDR_b_MtrB_ZeroTrq_Rqst
      VeSRMR_e_PPawl_Request: nonqueued-receiver-com-spec{data-element=Value, init-value=CePPCR_e_Req_No_Req}, required-interface=VeSRMR_e_PPawl_Request
      VeSRMR_e_VldtdTransShiftRngSt: nonqueued-receiver-com-spec{data-element=Value, init-value=CeTRGR_e_NoSelectionAvailable}, required-interface=VeSRMR_e_VldtdTransShiftRngSt
      VeHTDR_n_MtrA_SpdCmnd: variation-point={short-label=vpVeHTDR_n_MtrA_SpdCmnd, sw-syscond=1}, nonqueued-receiver-com-spec{data-element=Value, init-value=0}, required-interface=VeHTDR_n_MtrA_SpdCmnd
      VeHTDR_n_MtrB_SpdCmnd: nonqueued-receiver-com-spec{data-element=Value, init-value=0}, required-interface=VeHTDR_n_MtrB_SpdCmnd
      VeSRMR_v_VehSpd: nonqueued-receiver-com-spec{data-element=Value, init-value=0}, required-interface=VeSRMR_v_VehSpd
      VeSRMR_b_VehSpdFA: nonqueued-receiver-com-spec{data-element=Value, init-value=0}, required-interface=VeSRMR_b_VehSpdFA
      VePMPR_dV_FEDMFlw: nonqueued-receiver-com-spec{data-element=Value, init-value=0}, required-interface=VePMPR_dV_FEDMFlw
      VePMPR_b_FEDMFlw_FA: nonqueued-receiver-com-spec{data-element=Value, init-value=0}, required-interface=VePMPR_b_FEDMFlw_FA
      VePMPR_dV_REDMFlw: nonqueued-receiver-com-spec{data-element=Value, init-value=0}, required-interface=VePMPR_dV_REDMFlw
      VePMPR_b_REDMFlw_FA: nonqueued-receiver-com-spec{data-element=Value, init-value=0}, required-interface=VePMPR_b_REDMFlw_FA
      VeTRNR_b_InertiaTrqActv: variation-point={short-label=vpVeTRNR_b_InertiaTrqActv, sw-syscond=1}, nonqueued-receiver-com-spec{data-element=Value, init-value=0}, required-interface=VeTRNR_b_InertiaTrqActv
      VeCSVR_n_WhlSpdLHR: variation-point={short-label=vpVeCSVR_n_WhlSpdLHR, sw-syscond=1}, nonqueued-receiver-com-spec{data-element=Value, init-value=0}, required-interface=VeCSVR_n_WhlSpdLHR
      VeCSVR_n_WhlSpdRHR: variation-point={short-label=vpVeCSVR_n_WhlSpdRHR, sw-syscond=1}, nonqueued-receiver-com-spec{data-element=Value, init-value=0}, required-interface=VeCSVR_n_WhlSpdRHR
      VeTTQR_M_LoadTorqFront_Min: variation-point={short-label=vpVeTTQR_M_LoadTorqFront_Min, sw-syscond=1}, nonqueued-receiver-com-spec{data-element=Value, init-value=0}, required-interface=VeTTQR_M_LoadTorqFront_Min
      VeTTQR_M_LoadFrontOptShaped: variation-point={short-label=vpVeTTQR_M_LoadFrontOptShaped, sw-syscond=1}, nonqueued-receiver-com-spec{data-element=Value, init-value=0}, required-interface=VeTTQR_M_LoadFrontOptShaped
      VeTTQR_M_SumTrqAct_SEM: variation-point={short-label=vpVeTTQR_M_SumTrqAct_SEM, sw-syscond=1}, nonqueued-receiver-com-spec{data-element=Value, init-value=0}, required-interface=VeTTQR_M_SumTrqAct_SEM
      VeTTQR_M_LoadTorqFront_Opt: variation-point={short-label=vpVeTTQR_M_LoadTorqFront_Opt, sw-syscond=1}, nonqueued-receiver-com-spec{data-element=Value, init-value=0}, required-interface=VeTTQR_M_LoadTorqFront_Opt
      VeTTQR_M_LoadFrontOpt_xShaping: variation-point={short-label=vpVeTTQR_M_LoadFrontOpt_xShaping, sw-syscond=1}, nonqueued-receiver-com-spec{data-element=Value, init-value=0}, required-interface=VeTTQR_M_LoadFrontOpt_xShaping
      VeSRMR_e_EngCntrlMode: variation-point={short-label=vpVeSRMR_e_EngCntrlMode, sw-syscond=1}, nonqueued-receiver-com-spec{data-element=Value, init-value=0}, required-interface=VeSRMR_e_EngCntrlMode
      VeSRMR_M_EngTrqCmndImmed: variation-point={short-label=vpVeSRMR_M_EngTrqCmndImmed, sw-syscond=1}, nonqueued-receiver-com-spec{data-element=Value, init-value=0}, required-interface=VeSRMR_M_EngTrqCmndImmed
      VeSRMR_M_EngTrqCmndPrdtd: variation-point={short-label=vpVeSRMR_M_EngTrqCmndPrdtd, sw-syscond=1}, nonqueued-receiver-com-spec{data-element=Value, init-value=0}, required-interface=VeSRMR_M_EngTrqCmndPrdtd
      VeSRMR_e_HybCmndEngTorqRespTyp: variation-point={short-label=vpVeSRMR_e_HybCmndEngTorqRespTyp, sw-syscond=1}, nonqueued-receiver-com-spec{data-element=Value, init-value=0}, required-interface=VeSRMR_e_HybCmndEngTorqRespTyp
      VeSRMR_b_HybFeedback_ECM: variation-point={short-label=vpVeSRMR_b_HybFeedback_ECM, sw-syscond=1}, nonqueued-receiver-com-spec{data-element=Value, init-value=0}, required-interface=VeSRMR_b_HybFeedback_ECM
    40 x provide port:
      VeST2B_h_COMTX_AXLE_TORQUE_FD_1_FD3_Pkt: nonqueued-sender-com-spec{data-element=COMTX_AXLE_TORQUE_FD_1_FD3_Pkt, init-value={short-label=DefaultInitValue_IDTRAXLE_TORQUE_FD_1_FD3_Pkt, fields=[0, 0, 0, 0, 0, 0, 0, 0, 0, 0, 0, 0, 0, 0, 0, 0]}}, provided-interface=VeST2B_h_COMTX_AXLE_TORQUE_FD_1_FD3_Pkt
      VeST2B_h_COMTX_DRIVETRAIN_FD_3_FD3_Pkt: nonqueued-sender-com-spec{data-element=COMTX_DRIVETRAIN_FD_3_FD3_Pkt, init-value={short-label=DefaultInitValue_IDTRDRIVETRAIN_FD_3_FD3_Pkt, fields=[0, 0, 0, 0, 0, 0, 0, 0, 0, 0, 0, 0]}}, provided-interface=VeST2B_h_COMTX_DRIVETRAIN_FD_3_FD3_Pkt
      VeST2B_h_COMTX_ENGINE_SIMULATOR1_FD3_Pkt: nonqueued-sender-com-spec{data-element=COMTX_ENGINE_SIMULATOR1_FD3_Pkt, init-value={short-label=DefaultInitValue_IDTRENGINE_SIMULATOR1_FD3_Pkt, fields=[0, 0, 0, 0, 0, 0, 0, 0, 0, 0, 0, 0, 0, 0, 0, 0, 0, 0]}}, provided-interface=VeST2B_h_COMTX_ENGINE_SIMULATOR1_FD3_Pkt
      VeST2B_h_COMTX_HYBRID_DISPLAY_FD3_Pkt: nonqueued-sender-com-spec{data-element=COMTX_HYBRID_DISPLAY_FD3_Pkt, init-value={short-label=DefaultInitValue_IDTRHYBRID_DISPLAY_FD3_Pkt, fields=[0, 0, 0, 0, 0, 0, 0, 0, 0, 0, 0, 0, 0, 0, 0, 0, 0, 0, 0, 0, 0, 0, 0, 0, 0, 0, 0, 0, 0, 0, 0, 0, 0, 0, 0, 0, 0, 0, 0, 0]}}, provided-interface=VeST2B_h_COMTX_HYBRID_DISPLAY_FD3_Pkt
      VeST2B_h_COMTX_HYBRID_POWERTRAIN1_FD3_Pkt: nonqueued-sender-com-spec{data-element=COMTX_HYBRID_POWERTRAIN1_FD3_Pkt, init-value={short-label=DefaultInitValue_IDTRHYBRID_POWERTRAIN1_FD3_Pkt, fields=[0, 0, 0, 0, 0, 0, 0, 0, 0, 0, 0, 0, 0, 0, 0, 0, 0, 0, 0, 0, 0, 0, 0, 0, 0, 0, 0, 0, 0, 0, 0, 0, 0, 0]}}, provided-interface=VeST2B_h_COMTX_HYBRID_POWERTRAIN1_FD3_Pkt
      VeST2B_h_COMTX_HYBRID_POWERTRAIN2_FD3_Pkt: nonqueued-sender-com-spec{data-element=COMTX_HYBRID_POWERTRAIN2_FD3_Pkt, init-value={short-label=DefaultInitValue_IDTRHYBRID_POWERTRAIN2_FD3_Pkt, fields=[0, 0, 0, 0, 0, 0, 0, 0, 0, 0]}}, provided-interface=VeST2B_h_COMTX_HYBRID_POWERTRAIN2_FD3_Pkt
      VeST2B_h_COMTX_HYBRID_POWERTRAIN4_FD3_Pkt: nonqueued-sender-com-spec{data-element=COMTX_HYBRID_POWERTRAIN4_FD3_Pkt, init-value={short-label=DefaultInitValue_IDTRHYBRID_POWERTRAIN4_FD3_Pkt, fields=[0, 0, 0, 0]}}, provided-interface=VeST2B_h_COMTX_HYBRID_POWERTRAIN4_FD3_Pkt
      VeST2B_h_COMTX_HYBRID_POWERTRAIN5_FD3_Pkt: nonqueued-sender-com-spec{data-element=COMTX_HYBRID_POWERTRAIN5_FD3_Pkt, init-value={short-label=DefaultInitValue_IDTRHYBRID_POWERTRAIN5_FD3_Pkt, fields=[0, 0, 0, 0, 0, 0, 0, 0, 0, 0, 0, 0, 0, 0, 0, 0, 0, 0, 0, 0, 0, 0, 0]}}, provided-interface=VeST2B_h_COMTX_HYBRID_POWERTRAIN5_FD3_Pkt
      VeST2B_h_COMTX_PT_SYSTEM_FD_1_FD3_Pkt: nonqueued-sender-com-spec{data-element=COMTX_PT_SYSTEM_FD_1_FD3_Pkt, init-value={short-label=DefaultInitValue_IDTRPT_SYSTEM_FD_1_FD3_Pkt, fields=[0, 0, 0, 0, 0, 0, 0, 0, 0, 0, 0, 0, 0, 0, 0, 0, 0, 0, 0, 0, 0, 0, 0, 0, 0, 0, 0, 0, 0, 0, 0, 0, 0, 0, 0, 0, 0, 0, 0, 0, 0, 0, 0, 0, 0, 0, 0, 0, 0, 0, 0, 0, 0, 0, 0, 0, 0, 0]}}, provided-interface=VeST2B_h_COMTX_PT_SYSTEM_FD_1_FD3_Pkt
      VeST2B_h_COMTX_PT_TORQUE_FD_1_FD3_Pkt: nonqueued-sender-com-spec{data-element=COMTX_PT_TORQUE_FD_1_FD3_Pkt, init-value={short-label=DefaultInitValue_IDTRPT_TORQUE_FD_1_FD3_Pkt, fields=[0, 0, 0, 0, 0, 0, 0, 0, 0, 0, 0, 0, 0, 0, 0, 0, 0, 0, 0, 0, 0, 0]}}, provided-interface=VeST2B_h_COMTX_PT_TORQUE_FD_1_FD3_Pkt
      VeST2B_h_COMTX_TRANSM_FD_1_FD3_Pkt: nonqueued-sender-com-spec{data-element=COMTX_TRANSM_FD_1_FD3_Pkt, init-value={short-label=DefaultInitValue_IDTRTRANSM_FD_1_FD3_Pkt, fields=[0, 0, 0, 0, 0, 0, 0, 0, 0, 0, 0, 0, 0, 0, 0, 0, 0, 0, 0, 0, 0, 0, 0, 0, 0, 0, 0, 0, 0]}}, provided-interface=VeST2B_h_COMTX_TRANSM_FD_1_FD3_Pkt
      VeST2B_h_COMTX_TRANSM_FD_2_FD3_Pkt: nonqueued-sender-com-spec{data-element=COMTX_TRANSM_FD_2_FD3_Pkt, init-value={short-label=DefaultInitValue_IDTRTRANSM_FD_2_FD3_Pkt, fields=[0, 0, 0, 0, 0, 0, 0, 0, 0, 0, 0, 0, 0, 0, 0, 0, 0, 0, 0, 0, 0, 0, 0]}}, provided-interface=VeST2B_h_COMTX_TRANSM_FD_2_FD3_Pkt
      VeST2B_h_COMTX_VDCM_HMI_FD3_Pkt: nonqueued-sender-com-spec{data-element=COMTX_VDCM_HMI_FD3_Pkt, init-value={short-label=DefaultInitValue_IDTRVDCM_HMI_FD3_Pkt, fields=[0, 0, 0, 0, 0, 0, 0, 0, 0, 0, 0, 0, 0]}}, provided-interface=VeST2B_h_COMTX_VDCM_HMI_FD3_Pkt
      VeST2B_h_COMTX_EVCU_ISO15118_STATUS1_FD11_Pkt: nonqueued-sender-com-spec{data-element=COMTX_EVCU_ISO15118_STATUS1_FD11_Pkt, init-value={short-label=DefaultInitValue_IDTREVCU_ISO15118_STATUS1_FD11_Pkt, fields=[0, 0, 0, 0, 0, 0, 0, 0, 0, 0, 0, 0, 0, 0, 0, 0, 0, 0, 0, 0, 0, 0, 0, 0, 0, 0]}}, provided-interface=VeST2B_h_COMTX_EVCU_ISO15118_STATUS1_FD11_Pkt
      VeST2B_h_COMTX_HYBRID_CHARGING_COMMAND_FD11_Pkt: nonqueued-sender-com-spec{data-element=COMTX_HYBRID_CHARGING_COMMAND_FD11_Pkt, init-value={short-label=DefaultInitValue_IDTRHYBRID_CHARGING_COMMAND_FD11_Pkt, fields=[0, 0, 0, 0, 0, 0, 0, 0, 0, 0, 0, 0, 0, 0, 0, 0, 0, 0, 0, 0, 0, 0, 0, 0, 0, 0, 0, 0, 0, 0]}}, provided-interface=VeST2B_h_COMTX_HYBRID_CHARGING_COMMAND_FD11_Pkt
      VeST2B_h_COMTX_HYBRID_CHARGING_STATUS_FD11_Pkt: nonqueued-sender-com-spec{data-element=COMTX_HYBRID_CHARGING_STATUS_FD11_Pkt, init-value={short-label=DefaultInitValue_IDTRHYBRID_CHARGING_STATUS_FD11_Pkt, fields=[0, 0, 0, 0, 0, 0, 0, 0, 0, 0, 0, 0, 0]}}, provided-interface=VeST2B_h_COMTX_HYBRID_CHARGING_STATUS_FD11_Pkt
      VeST2B_h_COMTX_HYBRID_POWERTRAIN1_FD11_Pkt: nonqueued-sender-com-spec{data-element=COMTX_HYBRID_POWERTRAIN1_FD11_Pkt, init-value={short-label=DefaultInitValue_IDTRHYBRID_POWERTRAIN1_FD11_Pkt, fields=[0, 0]}}, provided-interface=VeST2B_h_COMTX_HYBRID_POWERTRAIN1_FD11_Pkt
      VeST2B_h_COMTX_PT_ENERGY_FD_1_FD11_Pkt: nonqueued-sender-com-spec{data-element=COMTX_PT_ENERGY_FD_1_FD11_Pkt, init-value={short-label=DefaultInitValue_IDTRPT_ENERGY_FD_1_FD11_Pkt, fields=[0, 0, 0, 0, 0, 0, 0, 0, 0, 0, 0, 0, 0, 0, 0, 0, 0, 0, 0, 0, 0, 0, 0, 0, 0, 0, 0, 0, 0, 0]}}, provided-interface=VeST2B_h_COMTX_PT_ENERGY_FD_1_FD11_Pkt
      VeST2B_h_COMTX_RPF_FD_3_FD11_Pkt: nonqueued-sender-com-spec{data-element=COMTX_RPF_FD_3_FD11_Pkt, init-value={short-label=DefaultInitValue_IDTRRPF_FD_3_FD11_Pkt, fields=[0, 0, 0, 0, 0, 0]}}, provided-interface=VeST2B_h_COMTX_RPF_FD_3_FD11_Pkt
      VeST2B_h_COMTX_VDCM_OBCM2_FD11_Pkt: nonqueued-sender-com-spec{data-element=COMTX_VDCM_OBCM2_FD11_Pkt, init-value={short-label=DefaultInitValue_IDTRVDCM_OBCM2_FD11_Pkt, fields=[0, 0, 0, 0, 0, 0, 0, 0, 0, 0, 0, 0, 0, 0, 0, 0, 0, 0, 0, 0, 0, 0, 0, 0, 0, 0, 0, 0, 0, 0, 0, 0, 0, 0, 0, 0, 0, 0, 0, 0, 0, 0, 0, 0, 0, 0, 0, 0, 0, 0, 0, 0, 0, 0, 0, 0, 0, 0, 0, 0, 0, 0]}}, provided-interface=VeST2B_h_COMTX_VDCM_OBCM2_FD11_Pkt
      VeST2B_h_COMTX_AXLE_TORQUE_FD_1_FD14_Pkt: nonqueued-sender-com-spec{data-element=COMTX_AXLE_TORQUE_FD_1_FD14_Pkt, init-value={short-label=DefaultInitValue_IDTRAXLE_TORQUE_FD_1_FD14_Pkt, fields=[0, 0, 0, 0, 0, 0, 0, 0, 0, 0, 0, 0, 0, 0]}}, provided-interface=VeST2B_h_COMTX_AXLE_TORQUE_FD_1_FD14_Pkt
      VeST2B_h_COMTX_PT_SYSTEM_FD_1_FD14_Pkt: nonqueued-sender-com-spec{data-element=COMTX_PT_SYSTEM_FD_1_FD14_Pkt, init-value={short-label=DefaultInitValue_IDTRPT_SYSTEM_FD_1_FD14_Pkt, fields=[0, 0, 0, 0, 0, 0, 0, 0, 0, 0, 0, 0, 0, 0, 0, 0, 0, 0]}}, provided-interface=VeST2B_h_COMTX_PT_SYSTEM_FD_1_FD14_Pkt
      VeST2B_h_COMTX_PT_TORQUE_FD_1_FD14_Pkt: nonqueued-sender-com-spec{data-element=COMTX_PT_TORQUE_FD_1_FD14_Pkt, init-value={short-label=DefaultInitValue_IDTRPT_TORQUE_FD_1_FD14_Pkt, fields=[0, 0, 0, 0, 0, 0, 0, 0, 0, 0, 0, 0, 0, 0, 0, 0, 0]}}, provided-interface=VeST2B_h_COMTX_PT_TORQUE_FD_1_FD14_Pkt
      VeST2B_h_COMTX_HYBRID_POWERTRAIN1_FD16_Pkt: nonqueued-sender-com-spec{data-element=COMTX_HYBRID_POWERTRAIN1_FD16_Pkt, init-value={short-label=DefaultInitValue_IDTRHYBRID_POWERTRAIN1_FD16_Pkt, fields=[0, 0, 0, 0, 0, 0, 0, 0, 0, 0, 0, 0, 0, 0, 0, 0]}}, provided-interface=VeST2B_h_COMTX_HYBRID_POWERTRAIN1_FD16_Pkt
      VeST2B_h_COMTX_HYBRID_POWERTRAIN2_FD16_Pkt: nonqueued-sender-com-spec{data-element=COMTX_HYBRID_POWERTRAIN2_FD16_Pkt, init-value={short-label=DefaultInitValue_IDTRHYBRID_POWERTRAIN2_FD16_Pkt, fields=[0, 0, 0, 0, 0]}}, provided-interface=VeST2B_h_COMTX_HYBRID_POWERTRAIN2_FD16_Pkt
      VeST2B_h_COMTX_HYBRID_POWERTRAIN5_FD16_Pkt: nonqueued-sender-com-spec{data-element=COMTX_HYBRID_POWERTRAIN5_FD16_Pkt, init-value={short-label=DefaultInitValue_IDTRHYBRID_POWERTRAIN5_FD16_Pkt, fields=[0, 0, 0, 0, 0, 0]}}, provided-interface=VeST2B_h_COMTX_HYBRID_POWERTRAIN5_FD16_Pkt
      VeST2B_h_COMTX_INVTARGET_PROPULSION1_FD16_Pkt: nonqueued-sender-com-spec{data-element=COMTX_INVTARGET_PROPULSION1_FD16_Pkt, init-value={short-label=DefaultInitValue_IDTRINVTARGET_PROPULSION1_FD16_Pkt, fields=[0, 0, 0, 0, 0, 0, 0, 0, 0, 0, 0, 0, 0, 0, 0, 0, 0, 0, 0, 0, 0, 0, 0, 0, 0, 0, 0, 0, 0, 0, 0, 0, 0, 0, 0]}}, provided-interface=VeST2B_h_COMTX_INVTARGET_PROPULSION1_FD16_Pkt
      VeST2B_h_COMTX_INVTARGET_PROPULSION2_FD16_Pkt: nonqueued-sender-com-spec{data-element=COMTX_INVTARGET_PROPULSION2_FD16_Pkt, init-value={short-label=DefaultInitValue_IDTRINVTARGET_PROPULSION2_FD16_Pkt, fields=[0, 0, 0, 0, 0, 0, 0, 0, 0, 0, 0, 0, 0, 0, 0, 0, 0, 0, 0, 0]}}, provided-interface=VeST2B_h_COMTX_INVTARGET_PROPULSION2_FD16_Pkt
      VeST2B_h_COMTX_PT_SYSTEM_FD_1_FD16_Pkt: nonqueued-sender-com-spec{data-element=COMTX_PT_SYSTEM_FD_1_FD16_Pkt, init-value={short-label=DefaultInitValue_IDTRPT_SYSTEM_FD_1_FD16_Pkt, fields=[0, 0, 0, 0, 0, 0, 0, 0, 0, 0, 0, 0, 0, 0, 0, 0, 0, 0, 0, 0, 0, 0, 0, 0, 0, 0, 0, 0, 0]}}, provided-interface=VeST2B_h_COMTX_PT_SYSTEM_FD_1_FD16_Pkt
      VeST2B_h_COMTX_PT_TORQUE_FD_1_FD16_Pkt: nonqueued-sender-com-spec{data-element=COMTX_PT_TORQUE_FD_1_FD16_Pkt, init-value={short-label=DefaultInitValue_IDTRPT_TORQUE_FD_1_FD16_Pkt, fields=[0, 0, 0, 0, 0, 0, 0, 0, 0, 0]}}, provided-interface=VeST2B_h_COMTX_PT_TORQUE_FD_1_FD16_Pkt
      VeST2B_h_COMTX_HYBRID_CHARGING_COMMAND_FD5_Pkt: nonqueued-sender-com-spec{data-element=COMTX_HYBRID_CHARGING_COMMAND_FD5_Pkt, init-value={short-label=DefaultInitValue_IDTRHYBRID_CHARGING_COMMAND_FD5_Pkt, fields=[0, 0, 0, 0, 0, 0, 0, 0, 0, 0, 0, 0, 0, 0, 0, 0, 0]}}, provided-interface=VeST2B_h_COMTX_HYBRID_CHARGING_COMMAND_FD5_Pkt
      VeST2B_h_COMTX_HYBRID_CHARGING_STATUS_FD5_Pkt: nonqueued-sender-com-spec{data-element=COMTX_HYBRID_CHARGING_STATUS_FD5_Pkt, init-value={short-label=DefaultInitValue_IDTRHYBRID_CHARGING_STATUS_FD5_Pkt, fields=[0, 0, 0, 0, 0, 0, 0, 0, 0, 0, 0]}}, provided-interface=VeST2B_h_COMTX_HYBRID_CHARGING_STATUS_FD5_Pkt
      VeST2B_h_COMTX_HYBRID_FD_LHOM_FD5_Pkt: nonqueued-sender-com-spec{data-element=COMTX_HYBRID_FD_LHOM_FD5_Pkt, init-value={short-label=DefaultInitValue_IDTRHYBRID_FD_LHOM_FD5_Pkt, fields=[0, 0, 0, 0, 0, 0, 0, 0, 0, 0, 0, 0, 0, 0, 0]}}, provided-interface=VeST2B_h_COMTX_HYBRID_FD_LHOM_FD5_Pkt
      VeST2B_h_COMTX_HYBRID_POWERTRAIN1_FD5_Pkt: nonqueued-sender-com-spec{data-element=COMTX_HYBRID_POWERTRAIN1_FD5_Pkt, init-value={short-label=DefaultInitValue_IDTRHYBRID_POWERTRAIN1_FD5_Pkt, fields=[0, 0, 0, 0, 0, 0]}}, provided-interface=VeST2B_h_COMTX_HYBRID_POWERTRAIN1_FD5_Pkt
      VeST2B_h_COMTX_HYBRID_POWERTRAIN5_FD5_Pkt: nonqueued-sender-com-spec{data-element=COMTX_HYBRID_POWERTRAIN5_FD5_Pkt, init-value={short-label=DefaultInitValue_IDTRHYBRID_POWERTRAIN5_FD5_Pkt, fields=[0, 0, 0, 0, 0, 0]}}, provided-interface=VeST2B_h_COMTX_HYBRID_POWERTRAIN5_FD5_Pkt
      VeST2B_h_COMTX_INVTARGET_PROPULSION1_FD5_Pkt: nonqueued-sender-com-spec{data-element=COMTX_INVTARGET_PROPULSION1_FD5_Pkt, init-value={short-label=DefaultInitValue_IDTRINVTARGET_PROPULSION1_FD5_Pkt, fields=[0, 0, 0, 0, 0, 0, 0, 0, 0, 0, 0, 0, 0, 0, 0, 0, 0, 0, 0, 0, 0, 0, 0, 0, 0, 0, 0, 0, 0, 0, 0, 0, 0, 0, 0]}}, provided-interface=VeST2B_h_COMTX_INVTARGET_PROPULSION1_FD5_Pkt
      VeST2B_h_COMTX_INVTARGET_PROPULSION2_FD5_Pkt: nonqueued-sender-com-spec{data-element=COMTX_INVTARGET_PROPULSION2_FD5_Pkt, init-value={short-label=DefaultInitValue_IDTRINVTARGET_PROPULSION2_FD5_Pkt, fields=[0, 0, 0, 0, 0, 0, 0, 0, 0, 0, 0, 0, 0, 0, 0, 0, 0, 0, 0, 0]}}, provided-interface=VeST2B_h_COMTX_INVTARGET_PROPULSION2_FD5_Pkt
      VeST2B_h_COMTX_PT_ENERGY_FD_1_FD5_Pkt: nonqueued-sender-com-spec{data-element=COMTX_PT_ENERGY_FD_1_FD5_Pkt, init-value={short-label=DefaultInitValue_IDTRPT_ENERGY_FD_1_FD5_Pkt, fields=[0, 0, 0, 0, 0, 0, 0, 0, 0, 0, 0, 0, 0, 0, 0, 0, 0, 0, 0, 0, 0, 0, 0, 0]}}, provided-interface=VeST2B_h_COMTX_PT_ENERGY_FD_1_FD5_Pkt
      VeST2B_h_COMTX_PT_SYSTEM_FD_1_FD5_Pkt: nonqueued-sender-com-spec{data-element=COMTX_PT_SYSTEM_FD_1_FD5_Pkt, init-value={short-label=DefaultInitValue_IDTRPT_SYSTEM_FD_1_FD5_Pkt, fields=[0, 0, 0, 0, 0, 0, 0, 0, 0, 0, 0, 0, 0, 0, 0]}}, provided-interface=VeST2B_h_COMTX_PT_SYSTEM_FD_1_FD5_Pkt
      VeST2B_h_COMTX_VDCM_OBCM2_FD5_Pkt: nonqueued-sender-com-spec{data-element=COMTX_VDCM_OBCM2_FD5_Pkt, init-value={short-label=DefaultInitValue_IDTRVDCM_OBCM2_FD5_Pkt, fields=[0, 0, 0, 0, 0, 0, 0, 0, 0, 0, 0, 0, 0, 0, 0, 0, 0, 0, 0, 0, 0, 0, 0, 0, 0, 0, 0, 0, 0, 0, 0, 0, 0, 0, 0, 0, 0, 0, 0, 0, 0, 0, 0, 0, 0, 0, 0, 0, 0, 0, 0, 0, 0, 0, 0, 0, 0, 0, 0, 0, 0, 0]}}, provided-interface=VeST2B_h_COMTX_VDCM_OBCM2_FD5_Pkt
    require port ST2B_FUNC_FastTEF_StartCheckpoint: client-com-spec=CheckpointReached, required-interface=WdgM_LocalSupervision
    require port ST2B_FUNC_FastTEF_StopCheckpoint: client-com-spec=CheckpointReached, required-interface=WdgM_LocalSupervision
    behavior IB_ST2B_FUNC: data-type-mapping=msADTtoIDTMapping, handle-termination-and-restart=NO-SUPPORT
      timing event Event_FastTEF: start-on-event=ST2B_FUNC_FastTEF, period=0.005
      init event Event_ST2B_FUNC_ac_Init: start-on-event=ST2B_FUNC_ac_Init
      runnable ST2B_FUNC_ac_Init
        data-send-points:
          40 x access:
            OUT_VeST2B_h_COMTX_AXLE_TORQUE_FD_1_FD3_Pkt_COMTX_AXLE_TORQUE_FD_1_FD3_Pkt: accessed-variable=VeST2B_h_COMTX_AXLE_TORQUE_FD_1_FD3_Pkt.COMTX_AXLE_TORQUE_FD_1_FD3_Pkt
            OUT_VeST2B_h_COMTX_DRIVETRAIN_FD_3_FD3_Pkt_COMTX_DRIVETRAIN_FD_3_FD3_Pkt: accessed-variable=VeST2B_h_COMTX_DRIVETRAIN_FD_3_FD3_Pkt.COMTX_DRIVETRAIN_FD_3_FD3_Pkt
            OUT_VeST2B_h_COMTX_ENGINE_SIMULATOR1_FD3_Pkt_COMTX_ENGINE_SIMULATOR1_FD3_Pkt: accessed-variable=VeST2B_h_COMTX_ENGINE_SIMULATOR1_FD3_Pkt.COMTX_ENGINE_SIMULATOR1_FD3_Pkt
            OUT_VeST2B_h_COMTX_HYBRID_DISPLAY_FD3_Pkt_COMTX_HYBRID_DISPLAY_FD3_Pkt: accessed-variable=VeST2B_h_COMTX_HYBRID_DISPLAY_FD3_Pkt.COMTX_HYBRID_DISPLAY_FD3_Pkt
            OUT_VeST2B_h_COMTX_HYBRID_POWERTRAIN1_FD3_Pkt_COMTX_HYBRID_POWERTRAIN1_FD3_Pkt: accessed-variable=VeST2B_h_COMTX_HYBRID_POWERTRAIN1_FD3_Pkt.COMTX_HYBRID_POWERTRAIN1_FD3_Pkt
            OUT_VeST2B_h_COMTX_HYBRID_POWERTRAIN2_FD3_Pkt_COMTX_HYBRID_POWERTRAIN2_FD3_Pkt: accessed-variable=VeST2B_h_COMTX_HYBRID_POWERTRAIN2_FD3_Pkt.COMTX_HYBRID_POWERTRAIN2_FD3_Pkt
            OUT_VeST2B_h_COMTX_HYBRID_POWERTRAIN4_FD3_Pkt_COMTX_HYBRID_POWERTRAIN4_FD3_Pkt: accessed-variable=VeST2B_h_COMTX_HYBRID_POWERTRAIN4_FD3_Pkt.COMTX_HYBRID_POWERTRAIN4_FD3_Pkt
            OUT_VeST2B_h_COMTX_HYBRID_POWERTRAIN5_FD3_Pkt_COMTX_HYBRID_POWERTRAIN5_FD3_Pkt: accessed-variable=VeST2B_h_COMTX_HYBRID_POWERTRAIN5_FD3_Pkt.COMTX_HYBRID_POWERTRAIN5_FD3_Pkt
            OUT_VeST2B_h_COMTX_PT_SYSTEM_FD_1_FD3_Pkt_COMTX_PT_SYSTEM_FD_1_FD3_Pkt: accessed-variable=VeST2B_h_COMTX_PT_SYSTEM_FD_1_FD3_Pkt.COMTX_PT_SYSTEM_FD_1_FD3_Pkt
            OUT_VeST2B_h_COMTX_PT_TORQUE_FD_1_FD3_Pkt_COMTX_PT_TORQUE_FD_1_FD3_Pkt: accessed-variable=VeST2B_h_COMTX_PT_TORQUE_FD_1_FD3_Pkt.COMTX_PT_TORQUE_FD_1_FD3_Pkt
            OUT_VeST2B_h_COMTX_TRANSM_FD_1_FD3_Pkt_COMTX_TRANSM_FD_1_FD3_Pkt: accessed-variable=VeST2B_h_COMTX_TRANSM_FD_1_FD3_Pkt.COMTX_TRANSM_FD_1_FD3_Pkt
            OUT_VeST2B_h_COMTX_TRANSM_FD_2_FD3_Pkt_COMTX_TRANSM_FD_2_FD3_Pkt: accessed-variable=VeST2B_h_COMTX_TRANSM_FD_2_FD3_Pkt.COMTX_TRANSM_FD_2_FD3_Pkt
            OUT_VeST2B_h_COMTX_VDCM_HMI_FD3_Pkt_COMTX_VDCM_HMI_FD3_Pkt: accessed-variable=VeST2B_h_COMTX_VDCM_HMI_FD3_Pkt.COMTX_VDCM_HMI_FD3_Pkt
            OUT_VeST2B_h_COMTX_EVCU_ISO15118_STATUS1_FD11_Pkt_COMTX_EVCU_ISO15118_STATUS1_FD11_Pkt: accessed-variable=VeST2B_h_COMTX_EVCU_ISO15118_STATUS1_FD11_Pkt.COMTX_EVCU_ISO15118_STATUS1_FD11_Pkt
            OUT_VeST2B_h_COMTX_HYBRID_CHARGING_COMMAND_FD11_Pkt_COMTX_HYBRID_CHARGING_COMMAND_FD11_Pkt: accessed-variable=VeST2B_h_COMTX_HYBRID_CHARGING_COMMAND_FD11_Pkt.COMTX_HYBRID_CHARGING_COMMAND_FD11_Pkt
            OUT_VeST2B_h_COMTX_HYBRID_CHARGING_STATUS_FD11_Pkt_COMTX_HYBRID_CHARGING_STATUS_FD11_Pkt: accessed-variable=VeST2B_h_COMTX_HYBRID_CHARGING_STATUS_FD11_Pkt.COMTX_HYBRID_CHARGING_STATUS_FD11_Pkt
            OUT_VeST2B_h_COMTX_HYBRID_POWERTRAIN1_FD11_Pkt_COMTX_HYBRID_POWERTRAIN1_FD11_Pkt: accessed-variable=VeST2B_h_COMTX_HYBRID_POWERTRAIN1_FD11_Pkt.COMTX_HYBRID_POWERTRAIN1_FD11_Pkt
            OUT_VeST2B_h_COMTX_PT_ENERGY_FD_1_FD11_Pkt_COMTX_PT_ENERGY_FD_1_FD11_Pkt: accessed-variable=VeST2B_h_COMTX_PT_ENERGY_FD_1_FD11_Pkt.COMTX_PT_ENERGY_FD_1_FD11_Pkt
            OUT_VeST2B_h_COMTX_RPF_FD_3_FD11_Pkt_COMTX_RPF_FD_3_FD11_Pkt: accessed-variable=VeST2B_h_COMTX_RPF_FD_3_FD11_Pkt.COMTX_RPF_FD_3_FD11_Pkt
            OUT_VeST2B_h_COMTX_VDCM_OBCM2_FD11_Pkt_COMTX_VDCM_OBCM2_FD11_Pkt: accessed-variable=VeST2B_h_COMTX_VDCM_OBCM2_FD11_Pkt.COMTX_VDCM_OBCM2_FD11_Pkt
            OUT_VeST2B_h_COMTX_AXLE_TORQUE_FD_1_FD14_Pkt_COMTX_AXLE_TORQUE_FD_1_FD14_Pkt: accessed-variable=VeST2B_h_COMTX_AXLE_TORQUE_FD_1_FD14_Pkt.COMTX_AXLE_TORQUE_FD_1_FD14_Pkt
            OUT_VeST2B_h_COMTX_PT_SYSTEM_FD_1_FD14_Pkt_COMTX_PT_SYSTEM_FD_1_FD14_Pkt: accessed-variable=VeST2B_h_COMTX_PT_SYSTEM_FD_1_FD14_Pkt.COMTX_PT_SYSTEM_FD_1_FD14_Pkt
            OUT_VeST2B_h_COMTX_PT_TORQUE_FD_1_FD14_Pkt_COMTX_PT_TORQUE_FD_1_FD14_Pkt: accessed-variable=VeST2B_h_COMTX_PT_TORQUE_FD_1_FD14_Pkt.COMTX_PT_TORQUE_FD_1_FD14_Pkt
            OUT_VeST2B_h_COMTX_HYBRID_POWERTRAIN1_FD16_Pkt_COMTX_HYBRID_POWERTRAIN1_FD16_Pkt: accessed-variable=VeST2B_h_COMTX_HYBRID_POWERTRAIN1_FD16_Pkt.COMTX_HYBRID_POWERTRAIN1_FD16_Pkt
            OUT_VeST2B_h_COMTX_HYBRID_POWERTRAIN2_FD16_Pkt_COMTX_HYBRID_POWERTRAIN2_FD16_Pkt: accessed-variable=VeST2B_h_COMTX_HYBRID_POWERTRAIN2_FD16_Pkt.COMTX_HYBRID_POWERTRAIN2_FD16_Pkt
            OUT_VeST2B_h_COMTX_HYBRID_POWERTRAIN5_FD16_Pkt_COMTX_HYBRID_POWERTRAIN5_FD16_Pkt: accessed-variable=VeST2B_h_COMTX_HYBRID_POWERTRAIN5_FD16_Pkt.COMTX_HYBRID_POWERTRAIN5_FD16_Pkt
            OUT_VeST2B_h_COMTX_INVTARGET_PROPULSION1_FD16_Pkt_COMTX_INVTARGET_PROPULSION1_FD16_Pkt: accessed-variable=VeST2B_h_COMTX_INVTARGET_PROPULSION1_FD16_Pkt.COMTX_INVTARGET_PROPULSION1_FD16_Pkt
            OUT_VeST2B_h_COMTX_INVTARGET_PROPULSION2_FD16_Pkt_COMTX_INVTARGET_PROPULSION2_FD16_Pkt: accessed-variable=VeST2B_h_COMTX_INVTARGET_PROPULSION2_FD16_Pkt.COMTX_INVTARGET_PROPULSION2_FD16_Pkt
            OUT_VeST2B_h_COMTX_PT_SYSTEM_FD_1_FD16_Pkt_COMTX_PT_SYSTEM_FD_1_FD16_Pkt: accessed-variable=VeST2B_h_COMTX_PT_SYSTEM_FD_1_FD16_Pkt.COMTX_PT_SYSTEM_FD_1_FD16_Pkt
            OUT_VeST2B_h_COMTX_PT_TORQUE_FD_1_FD16_Pkt_COMTX_PT_TORQUE_FD_1_FD16_Pkt: accessed-variable=VeST2B_h_COMTX_PT_TORQUE_FD_1_FD16_Pkt.COMTX_PT_TORQUE_FD_1_FD16_Pkt
            OUT_VeST2B_h_COMTX_HYBRID_CHARGING_COMMAND_FD5_Pkt_COMTX_HYBRID_CHARGING_COMMAND_FD5_Pkt: accessed-variable=VeST2B_h_COMTX_HYBRID_CHARGING_COMMAND_FD5_Pkt.COMTX_HYBRID_CHARGING_COMMAND_FD5_Pkt
            OUT_VeST2B_h_COMTX_HYBRID_CHARGING_STATUS_FD5_Pkt_COMTX_HYBRID_CHARGING_STATUS_FD5_Pkt: accessed-variable=VeST2B_h_COMTX_HYBRID_CHARGING_STATUS_FD5_Pkt.COMTX_HYBRID_CHARGING_STATUS_FD5_Pkt
            OUT_VeST2B_h_COMTX_HYBRID_FD_LHOM_FD5_Pkt_COMTX_HYBRID_FD_LHOM_FD5_Pkt: accessed-variable=VeST2B_h_COMTX_HYBRID_FD_LHOM_FD5_Pkt.COMTX_HYBRID_FD_LHOM_FD5_Pkt
            OUT_VeST2B_h_COMTX_HYBRID_POWERTRAIN1_FD5_Pkt_COMTX_HYBRID_POWERTRAIN1_FD5_Pkt: accessed-variable=VeST2B_h_COMTX_HYBRID_POWERTRAIN1_FD5_Pkt.COMTX_HYBRID_POWERTRAIN1_FD5_Pkt
            OUT_VeST2B_h_COMTX_HYBRID_POWERTRAIN5_FD5_Pkt_COMTX_HYBRID_POWERTRAIN5_FD5_Pkt: accessed-variable=VeST2B_h_COMTX_HYBRID_POWERTRAIN5_FD5_Pkt.COMTX_HYBRID_POWERTRAIN5_FD5_Pkt
            OUT_VeST2B_h_COMTX_INVTARGET_PROPULSION1_FD5_Pkt_COMTX_INVTARGET_PROPULSION1_FD5_Pkt: accessed-variable=VeST2B_h_COMTX_INVTARGET_PROPULSION1_FD5_Pkt.COMTX_INVTARGET_PROPULSION1_FD5_Pkt
            OUT_VeST2B_h_COMTX_INVTARGET_PROPULSION2_FD5_Pkt_COMTX_INVTARGET_PROPULSION2_FD5_Pkt: accessed-variable=VeST2B_h_COMTX_INVTARGET_PROPULSION2_FD5_Pkt.COMTX_INVTARGET_PROPULSION2_FD5_Pkt
            OUT_VeST2B_h_COMTX_PT_ENERGY_FD_1_FD5_Pkt_COMTX_PT_ENERGY_FD_1_FD5_Pkt: accessed-variable=VeST2B_h_COMTX_PT_ENERGY_FD_1_FD5_Pkt.COMTX_PT_ENERGY_FD_1_FD5_Pkt
            OUT_VeST2B_h_COMTX_PT_SYSTEM_FD_1_FD5_Pkt_COMTX_PT_SYSTEM_FD_1_FD5_Pkt: accessed-variable=VeST2B_h_COMTX_PT_SYSTEM_FD_1_FD5_Pkt.COMTX_PT_SYSTEM_FD_1_FD5_Pkt
            OUT_VeST2B_h_COMTX_VDCM_OBCM2_FD5_Pkt_COMTX_VDCM_OBCM2_FD5_Pkt: accessed-variable=VeST2B_h_COMTX_VDCM_OBCM2_FD5_Pkt.COMTX_VDCM_OBCM2_FD5_Pkt
      runnable ST2B_FUNC_FastTEF
        data-receive-point-by-arguments:
          282 x access:
            IN_VeADCR_e_AWDSysStat_Value: accessed-variable=VeADCR_e_AWDSysStat.Value
            IN_VeADCR_i_WEDAxleStat_CAN_Value: accessed-variable=VeADCR_i_WEDAxleStat_CAN.Value
            IN_VeAPSR_U_RawPVS1_Value: accessed-variable=VeAPSR_U_RawPVS1.Value
            IN_VeAPSR_U_RawPVS2_Value: accessed-variable=VeAPSR_U_RawPVS2.Value
            IN_VeAPSR_b_Lv1PvBrkActive_Value: accessed-variable=VeAPSR_b_Lv1PvBrkActive.Value
            IN_VeASLR_b_ISASts_Value: accessed-variable=VeASLR_b_ISASts.Value
            IN_VeASLR_e_DrvMdOvrrdKickdownSt_Value: accessed-variable=VeASLR_e_DrvMdOvrrdKickdownSt.Value
            IN_VeASLR_e_SpdLmtSts_Value: accessed-variable=VeASLR_e_SpdLmtSts.Value
            IN_VeAXLR_M_FrntAxlTrqMax_Value: accessed-variable=VeAXLR_M_FrntAxlTrqMax.Value
            IN_VeAXLR_M_FrntAxlTrqMin_Value: accessed-variable=VeAXLR_M_FrntAxlTrqMin.Value
            IN_VeAXLR_M_RrAxlTrqMax_Value: accessed-variable=VeAXLR_M_RrAxlTrqMax.Value
            IN_VeAXLR_M_RrAxlTrqMin_Value: accessed-variable=VeAXLR_M_RrAxlTrqMin.Value
            IN_VeAXLR_M_SplitFrntTrqReq_Value: accessed-variable=VeAXLR_M_SplitFrntTrqReq.Value
            IN_VeAXLR_M_SplitRrAxlTrqReq_Value: accessed-variable=VeAXLR_M_SplitRrAxlTrqReq.Value
            IN_VeBACR_r_ElecPwrTorq_PedalFact_Value: accessed-variable=VeBACR_r_ElecPwrTorq_PedalFact.Value
            IN_VeBPCR_I_HV_BatCurr_Value: accessed-variable=VeBPCR_I_HV_BatCurr.Value
            IN_VeBPCR_U_HV_BatVolt_Value: accessed-variable=VeBPCR_U_HV_BatVolt.Value
            IN_VeBPCR_b_HV_BatCurrFA_Value: accessed-variable=VeBPCR_b_HV_BatCurrFA.Value
            IN_VeBPCR_b_HV_BatPackSOC_FA_Ovrd_Value: accessed-variable=VeBPCR_b_HV_BatPackSOC_FA_Ovrd.Value
            IN_VeBPCR_b_HV_BatVoltFA_Value: accessed-variable=VeBPCR_b_HV_BatVoltFA.Value
            IN_VeBPCR_e_HV_BatCntctrStat_Value: accessed-variable=VeBPCR_e_HV_BatCntctrStat.Value
            IN_VeCCTR_b_CcEngaged_Value: accessed-variable=VeCCTR_b_CcEngaged.Value
            IN_VeCCTR_b_CcLampSts_Value: accessed-variable=VeCCTR_b_CcLampSts.Value
            IN_VeCCTR_v_CcCntrlSpd_Cluster_KPH_Value: accessed-variable=VeCCTR_v_CcCntrlSpd_Cluster_KPH.Value
            IN_VeCCTR_v_CcCntrlSpd_Cluster_MPH_Value: accessed-variable=VeCCTR_v_CcCntrlSpd_Cluster_MPH.Value
            IN_VeCOMR_b_Random3_Value: accessed-variable=VeCOMR_b_Random3.Value
            IN_VeCSVR_n_WhlSpdLHR_Value: accessed-variable=VeCSVR_n_WhlSpdLHR.Value, variation-point={short-label=vpIN_VeCSVR_n_WhlSpdLHR_Value, sw-syscond=1}
            IN_VeCSVR_n_WhlSpdRHR_Value: accessed-variable=VeCSVR_n_WhlSpdRHR.Value, variation-point={short-label=vpIN_VeCSVR_n_WhlSpdRHR_Value, sw-syscond=1}
            IN_VeDMDR_e_TurtleMdSts_Value: accessed-variable=VeDMDR_e_TurtleMdSts.Value
            IN_VeDMIR_e_EcoLEDOn_Value: accessed-variable=VeDMIR_e_EcoLEDOn.Value, variation-point={short-label=vpIN_VeDMIR_e_EcoLEDOn_Value, sw-syscond=1}
            IN_VeDMIR_e_PaddleModeSts_Value: accessed-variable=VeDMIR_e_PaddleModeSts.Value
            IN_VeDMIR_e_TellTaleInfo_Value: accessed-variable=VeDMIR_e_TellTaleInfo.Value
            IN_VeDTRR_Pct_AccelPdlVirtActPosn_Value: accessed-variable=VeDTRR_Pct_AccelPdlVirtActPosn.Value
            IN_VeDTRR_b_DrvrIntndedAxleTrqRawFA_Value: accessed-variable=VeDTRR_b_DrvrIntndedAxleTrqRawFA.Value
            IN_VeDTRR_b_EngTrqEnblRqDAS_Value: accessed-variable=VeDTRR_b_EngTrqEnblRqDAS.Value
            IN_VeDTRR_b_PtcCcDriverOverride_Value: accessed-variable=VeDTRR_b_PtcCcDriverOverride.Value
            IN_VeDTRR_e_OPD_HMI_Value: accessed-variable=VeDTRR_e_OPD_HMI.Value
            IN_VeERER_b_EstRange_SNA_Value: accessed-variable=VeERER_b_EstRange_SNA.Value
            IN_VeERER_l_EstRange_Value: accessed-variable=VeERER_l_EstRange.Value
            IN_VeERER_l_EstRange_ChrgStpTime_Value: accessed-variable=VeERER_l_EstRange_ChrgStpTime.Value
            IN_VeESSR_b_EngOffAllwdECM_Value: accessed-variable=VeESSR_b_EngOffAllwdECM.Value
            IN_VeESSR_b_HCP_StopStart_Fault_Value: accessed-variable=VeESSR_b_HCP_StopStart_Fault.Value
            IN_VeESSR_e_EngStrtStpMd_Value: accessed-variable=VeESSR_e_EngStrtStpMd.Value
            IN_VeGENR_I_APMIdcHvSetP_Value: accessed-variable=VeGENR_I_APMIdcHvSetP.Value
            IN_VeGENR_I_APM_IdcLvSetP_Value: accessed-variable=VeGENR_I_APM_IdcLvSetP.Value
            IN_VeGENR_U_IBS_BattVoltOut_Value: accessed-variable=VeGENR_U_IBS_BattVoltOut.Value
            IN_VeGENR_U_SetPVoltRq_Value: accessed-variable=VeGENR_U_SetPVoltRq.Value
            IN_VeGENR_b_APMIdcHvSetPFA_Value: accessed-variable=VeGENR_b_APMIdcHvSetPFA.Value
            IN_VeGENR_b_HybGenSPDtyCycPtOverAct_Value: accessed-variable=VeGENR_b_HybGenSPDtyCycPtOverAct.Value
            IN_VeGENR_b_LowVoltSysFldToECM_Value: accessed-variable=VeGENR_b_LowVoltSysFldToECM.Value
            IN_VeGENR_b_SetPVoltRqFA_Value: accessed-variable=VeGENR_b_SetPVoltRqFA.Value
            IN_VeGENR_b_SrvcBattReChrgFlSts_Value: accessed-variable=VeGENR_b_SrvcBattReChrgFlSts.Value
            IN_VeGENR_e_stModeReq_Value: accessed-variable=VeGENR_e_stModeReq.Value
            IN_VeHADR_b_EngActDmpgDsblReq_Value: accessed-variable=VeHADR_b_EngActDmpgDsblReq.Value
            IN_VeHMIR_P_BatPwrUsageDisp_Value: accessed-variable=VeHMIR_P_BatPwrUsageDisp.Value
            IN_VeHMIR_P_EngPwrUsageDisp_Value: accessed-variable=VeHMIR_P_EngPwrUsageDisp.Value
            IN_VeHMIR_P_HVACPwrUsageDisp_Value: accessed-variable=VeHMIR_P_HVACPwrUsageDisp.Value
            IN_VeHMIR_P_MtrAPwrUsageDisp_Value: accessed-variable=VeHMIR_P_MtrAPwrUsageDisp.Value, variation-point={short-label=vpIN_VeHMIR_P_MtrAPwrUsageDisp_Value, sw-syscond=1}
            IN_VeHMIR_P_MtrAPwrUsageDispV_Value: accessed-variable=VeHMIR_P_MtrAPwrUsageDispV.Value, variation-point={short-label=vpIN_VeHMIR_P_MtrAPwrUsageDispV_Value, sw-syscond=1}
            IN_VeHMIR_P_MtrBPwrUsageDisp_Value: accessed-variable=VeHMIR_P_MtrBPwrUsageDisp.Value
            IN_VeHMIR_P_MtrBPwrUsageDispV_Value: accessed-variable=VeHMIR_P_MtrBPwrUsageDispV.Value
            IN_VeHMIR_P_MtrPwrUsageDisp_Value: accessed-variable=VeHMIR_P_MtrPwrUsageDisp.Value
            IN_VeHMIR_Pct_CoachDisp_Value: accessed-variable=VeHMIR_Pct_CoachDisp.Value
            IN_VeHMIR_Pct_EstSOCDisplay_Value: accessed-variable=VeHMIR_Pct_EstSOCDisplay.Value
            IN_VeHMIR_Pct_HVBatSOC_HCP_Value: accessed-variable=VeHMIR_Pct_HVBatSOC_HCP.Value
            IN_VeHMIR_Pct_OutputPwrDisp_Value: accessed-variable=VeHMIR_Pct_OutputPwrDisp.Value
            IN_VeHMIR_b_BatPwrUsageDispV_Value: accessed-variable=VeHMIR_b_BatPwrUsageDispV.Value
            IN_VeHMIR_b_CoachDispV_Value: accessed-variable=VeHMIR_b_CoachDispV.Value
            IN_VeHMIR_b_DriveReady_Value: accessed-variable=VeHMIR_b_DriveReady.Value
            IN_VeHMIR_b_DrvAwayAlt_Value: accessed-variable=VeHMIR_b_DrvAwayAlt.Value
            IN_VeHMIR_b_DrvAwayIn_Value: accessed-variable=VeHMIR_b_DrvAwayIn.Value
            IN_VeHMIR_b_EngPwrUsageDispV_Value: accessed-variable=VeHMIR_b_EngPwrUsageDispV.Value
            IN_VeHMIR_b_HEV_EVT_MD_Value: accessed-variable=VeHMIR_b_HEV_EVT_MD.Value
            IN_VeHMIR_b_HVACPwrUsageDispV_Value: accessed-variable=VeHMIR_b_HVACPwrUsageDispV.Value
            IN_VeHMIR_b_MtrPwrUsageDispV_Value: accessed-variable=VeHMIR_b_MtrPwrUsageDispV.Value
            IN_VeHMIR_b_OutputPwrDispV_Value: accessed-variable=VeHMIR_b_OutputPwrDispV.Value
            IN_VeHMIR_b_Popup_Msg1_Value: accessed-variable=VeHMIR_b_Popup_Msg1.Value, variation-point={short-label=vpIN_VeHMIR_b_Popup_Msg1_Value, sw-syscond=1}
            IN_VeHMIR_b_Popup_Msg10_Value: accessed-variable=VeHMIR_b_Popup_Msg10.Value
            IN_VeHMIR_b_Popup_Msg11_Value: accessed-variable=VeHMIR_b_Popup_Msg11.Value
            IN_VeHMIR_b_Popup_Msg{2..7}_Value: accessed-variable=VeHMIR_b_Popup_Msg{2..7}.Value
            IN_VeHMIR_b_ThrmlRnAway_Lmp_Value: accessed-variable=VeHMIR_b_ThrmlRnAway_Lmp.Value
            IN_VeHMIR_e_DriveMdstat_Value: accessed-variable=VeHMIR_e_DriveMdstat.Value
            IN_VeHMIR_e_DriveMdstat_PopUpRqst_Value: accessed-variable=VeHMIR_e_DriveMdstat_PopUpRqst.Value
            IN_VeHMIR_e_HEV_LMP_RQ_Value: accessed-variable=VeHMIR_e_HEV_LMP_RQ.Value
            IN_VeHMIR_e_TerrainHMIRq_Value: accessed-variable=VeHMIR_e_TerrainHMIRq.Value
            IN_VeHMIR_e_TerrainModeDesiredStat_Value: accessed-variable=VeHMIR_e_TerrainModeDesiredStat.Value
            IN_VeHMIR_e_TerrainModeStat_Value: accessed-variable=VeHMIR_e_TerrainModeStat.Value
            IN_VeHMIR_e_TransWarn2_Value: accessed-variable=VeHMIR_e_TransWarn2.Value
            IN_VeHMIR_e_VDCM_PopUpChrgPrtMis_Value: accessed-variable=VeHMIR_e_VDCM_PopUpChrgPrtMis.Value
            IN_VeHMIR_e_eBoost_Sts_Value: accessed-variable=VeHMIR_e_eBoost_Sts.Value, variation-point={short-label=vpIN_VeHMIR_e_eBoost_Sts_Value, sw-syscond=1}
            IN_VeHMIR_e_eBoost_Warn_Value: accessed-variable=VeHMIR_e_eBoost_Warn.Value, variation-point={short-label=vpIN_VeHMIR_e_eBoost_Warn_Value, sw-syscond=1}
            IN_VeHPMR_b_EVCURespAuxLoadOff_Value: accessed-variable=VeHPMR_b_EVCURespAuxLoadOff.Value
            IN_VeHPMR_b_PropSysActv_Value: accessed-variable=VeHPMR_b_PropSysActv.Value
            IN_VeHSER_e_RngStOnCAN_Value: accessed-variable=VeHSER_e_RngStOnCAN.Value
            IN_VeHSER_e_RngStToPropulsionMode_Value: accessed-variable=VeHSER_e_RngStToPropulsionMode.Value
            IN_VeHSER_n_InputSpeedProfile_Value: accessed-variable=VeHSER_n_InputSpeedProfile.Value
            IN_VeHTDR_M_MtrA_AEMDNegTrqOffst_Value: accessed-variable=VeHTDR_M_MtrA_AEMDNegTrqOffst.Value, variation-point={short-label=vpIN_VeHTDR_M_MtrA_AEMDNegTrqOffst_Value, sw-syscond=1}
            IN_VeHTDR_M_MtrA_AEMDPosTrqOffst_Value: accessed-variable=VeHTDR_M_MtrA_AEMDPosTrqOffst.Value, variation-point={short-label=vpIN_VeHTDR_M_MtrA_AEMDPosTrqOffst_Value, sw-syscond=1}
            IN_VeHTDR_M_MtrB_AEMDNegTrqOffst_Value: accessed-variable=VeHTDR_M_MtrB_AEMDNegTrqOffst.Value
            IN_VeHTDR_M_MtrB_AEMDPosTrqOffst_Value: accessed-variable=VeHTDR_M_MtrB_AEMDPosTrqOffst.Value
            IN_VeHTDR_b_MtrA_ZeroTrq_Rqst_Value: accessed-variable=VeHTDR_b_MtrA_ZeroTrq_Rqst.Value, variation-point={short-label=vpIN_VeHTDR_b_MtrA_ZeroTrq_Rqst_Value, sw-syscond=1}
            IN_VeHTDR_b_MtrB_ZeroTrq_Rqst_Value: accessed-variable=VeHTDR_b_MtrB_ZeroTrq_Rqst.Value
            IN_VeHTDR_f_MtrA_AEMDFc_Hi_Value: accessed-variable=VeHTDR_f_MtrA_AEMDFc_Hi.Value
            IN_VeHTDR_f_MtrA_AEMDFc_Lo_Value: accessed-variable=VeHTDR_f_MtrA_AEMDFc_Lo.Value
            IN_VeHTDR_f_MtrB_AEMDFc_Hi_Value: accessed-variable=VeHTDR_f_MtrB_AEMDFc_Hi.Value
            IN_VeHTDR_f_MtrB_AEMDFc_Lo_Value: accessed-variable=VeHTDR_f_MtrB_AEMDFc_Lo.Value
            IN_VeHTDR_n_MtrA_SpdCmnd_Value: accessed-variable=VeHTDR_n_MtrA_SpdCmnd.Value, variation-point={short-label=vpIN_VeHTDR_n_MtrA_SpdCmnd_Value, sw-syscond=1}
            IN_VeHTDR_n_MtrB_SpdCmnd_Value: accessed-variable=VeHTDR_n_MtrB_SpdCmnd.Value
            IN_VeHTDR_scl_MtrA_AEMDPGainScl_Value: accessed-variable=VeHTDR_scl_MtrA_AEMDPGainScl.Value, variation-point={short-label=vpIN_VeHTDR_scl_MtrA_AEMDPGainScl_Value, sw-syscond=1}
            IN_VeHTDR_scl_MtrB_AEMDPGainScl_Value: accessed-variable=VeHTDR_scl_MtrB_AEMDPGainScl.Value
            IN_VeHVTR_U_HV_Volt_Value: accessed-variable=VeHVTR_U_HV_Volt.Value
            IN_VeHVTR_b_HV_VoltFA_Value: accessed-variable=VeHVTR_b_HV_VoltFA.Value
            IN_VeICSR_b_AdvancePrepForIdle_Value: accessed-variable=VeICSR_b_AdvancePrepForIdle.Value
            IN_VeMSPR_b_MtrA_SpdFA_Value: accessed-variable=VeMSPR_b_MtrA_SpdFA.Value, variation-point={short-label=vpIN_VeMSPR_b_MtrA_SpdFA_Value, sw-syscond=1}
            IN_VeMSPR_b_MtrB_SpdFA_Value: accessed-variable=VeMSPR_b_MtrB_SpdFA.Value, variation-point={short-label=vpIN_VeMSPR_b_MtrB_SpdFA_Value, sw-syscond=1}
            IN_VeMSPR_n_MtrA_Spd_Value: accessed-variable=VeMSPR_n_MtrA_Spd.Value, variation-point={short-label=vpIN_VeMSPR_n_MtrA_Spd_Value, sw-syscond=1}
            IN_VeMSPR_n_MtrB_Spd_Value: accessed-variable=VeMSPR_n_MtrB_Spd.Value, variation-point={short-label=vpIN_VeMSPR_n_MtrB_Spd_Value, sw-syscond=1}
            IN_VeMTIR_M_MtrA_TorqAchieved_Value: accessed-variable=VeMTIR_M_MtrA_TorqAchieved.Value, variation-point={short-label=vpIN_VeMTIR_M_MtrA_TorqAchieved_Value, sw-syscond=1}
            IN_VeMTIR_M_MtrB_TorqAchieved_Value: accessed-variable=VeMTIR_M_MtrB_TorqAchieved.Value, variation-point={short-label=vpIN_VeMTIR_M_MtrB_TorqAchieved_Value, sw-syscond=1}
            IN_VeOBCR_E_EVEnergyCapacity_Value: accessed-variable=VeOBCR_E_EVEnergyCapacity.Value
            IN_VeOBCR_E_EVEnergyRequest_Value: accessed-variable=VeOBCR_E_EVEnergyRequest.Value
            IN_VeOBCR_I_ChrgCrntReqDelta_Value: accessed-variable=VeOBCR_I_ChrgCrntReqDelta.Value
            IN_VeOBCR_I_EVMax_I_Limit_Value: accessed-variable=VeOBCR_I_EVMax_I_Limit.Value
            IN_VeOBCR_I_MaxAllowableCrntAC_Value: accessed-variable=VeOBCR_I_MaxAllowableCrntAC.Value
            IN_VeOBCR_I_MaxAllowableCrntBatt_Value: accessed-variable=VeOBCR_I_MaxAllowableCrntBatt.Value
            IN_VeOBCR_Pct_BattFullSOC_Value: accessed-variable=VeOBCR_Pct_BattFullSOC.Value
            IN_VeOBCR_U_ChrgVltReqDelta_Value: accessed-variable=VeOBCR_U_ChrgVltReqDelta.Value
            IN_VeOBCR_U_EVMax_V_Limit_Value: accessed-variable=VeOBCR_U_EVMax_V_Limit.Value
            IN_VeOBCR_U_MaxAllowableBattVolt_Value: accessed-variable=VeOBCR_U_MaxAllowableBattVolt.Value
            IN_VeOBCR_U_MinAllowableBattVolt_Value: accessed-variable=VeOBCR_U_MinAllowableBattVolt.Value
            IN_VeOBCR_b_BattOverVolt_Value: accessed-variable=VeOBCR_b_BattOverVolt.Value
            IN_VeOBCR_b_BattUnderVolt_Value: accessed-variable=VeOBCR_b_BattUnderVolt.Value
            IN_VeOBCR_b_CPIM_Error_Value: accessed-variable=VeOBCR_b_CPIM_Error.Value
            IN_VeOBCR_b_CPIM_OT_Value: accessed-variable=VeOBCR_b_CPIM_OT.Value
            IN_VeOBCR_b_ChrgSysFault_Value: accessed-variable=VeOBCR_b_ChrgSysFault.Value
            IN_VeOBCR_b_ChrgSysFaultBPCM_Value: accessed-variable=VeOBCR_b_ChrgSysFaultBPCM.Value
            IN_VeOBCR_b_CloseS2Cntctr_Value: accessed-variable=VeOBCR_b_CloseS2Cntctr.Value
            IN_VeOBCR_b_DCChrgInitialization_Value: accessed-variable=VeOBCR_b_DCChrgInitialization.Value
            IN_VeOBCR_b_DC_Isolation_Cmd_Value: accessed-variable=VeOBCR_b_DC_Isolation_Cmd.Value
            IN_VeOBCR_b_EnblChrg_Value: accessed-variable=VeOBCR_b_EnblChrg.Value
            IN_VeOBCR_b_HCP_SessionStpCmd_Value: accessed-variable=VeOBCR_b_HCP_SessionStpCmd.Value
            IN_VeOBCR_b_PluggedIn_Value: accessed-variable=VeOBCR_b_PluggedIn.Value
            IN_VeOBCR_b_SelectSecProtocol_Value: accessed-variable=VeOBCR_b_SelectSecProtocol.Value
            IN_VeOBCR_b_WeldChkComplete_Value: accessed-variable=VeOBCR_b_WeldChkComplete.Value
            IN_VeOBCR_e_BattTemp_OOR_Value: accessed-variable=VeOBCR_e_BattTemp_OOR.Value
            IN_VeOBCR_e_CellVolt_OOR_Value: accessed-variable=VeOBCR_e_CellVolt_OOR.Value
            IN_VeOBCR_e_ChargeProgress_Value: accessed-variable=VeOBCR_e_ChargeProgress.Value
            IN_VeOBCR_e_ChargingLevel_Value: accessed-variable=VeOBCR_e_ChargingLevel.Value
            IN_VeOBCR_e_ChargingSystemSts_Value: accessed-variable=VeOBCR_e_ChargingSystemSts.Value
            IN_VeOBCR_e_ChrgCurr_OOR_Value: accessed-variable=VeOBCR_e_ChrgCurr_OOR.Value
            IN_VeOBCR_e_ChrgrModeReq_Value: accessed-variable=VeOBCR_e_ChrgrModeReq.Value
            IN_VeOBCR_e_ChrgrTrsfMethodReq_Value: accessed-variable=VeOBCR_e_ChrgrTrsfMethodReq.Value
            IN_VeOBCR_e_DC_ChrgTypeCmd_Value: accessed-variable=VeOBCR_e_DC_ChrgTypeCmd.Value
            IN_VeOBCR_e_DC_CntctrCmd_Value: accessed-variable=VeOBCR_e_DC_CntctrCmd.Value
            IN_VeOBCR_e_HCP_DC_Retry_Value: accessed-variable=VeOBCR_e_HCP_DC_Retry.Value
            IN_VeOBCR_e_HCP_EVErrorCode_Value: accessed-variable=VeOBCR_e_HCP_EVErrorCode.Value
            IN_VeOBCR_e_Protocol_Priority{1..3}_Value: accessed-variable=VeOBCR_e_Protocol_Priority{1..3}.Value
            IN_VeOBCR_e_SOC_OOR_Value: accessed-variable=VeOBCR_e_SOC_OOR.Value
            IN_VeOBCR_e_SelectAppProtocol_Value: accessed-variable=VeOBCR_e_SelectAppProtocol.Value
            IN_VeOBCR_k_ChrgSysFault_Reason_Value: accessed-variable=VeOBCR_k_ChrgSysFault_Reason.Value
            IN_VeOBCR_k_MaxEntriesSASScheduleTuple_Value: accessed-variable=VeOBCR_k_MaxEntriesSASScheduleTuple.Value
            IN_VeOBCR_t_EstTimeDCFastChrg_100_Value: accessed-variable=VeOBCR_t_EstTimeDCFastChrg_100.Value
            IN_VeOBCR_t_EstTimeDCFastChrg_80_Value: accessed-variable=VeOBCR_t_EstTimeDCFastChrg_80.Value
            IN_VeOBCR_t_EstTimeofChrg_Lv1_Value: accessed-variable=VeOBCR_t_EstTimeofChrg_Lv1.Value
            IN_VeOBCR_t_EstTimeofChrg_Lv2_Value: accessed-variable=VeOBCR_t_EstTimeofChrg_Lv2.Value
            IN_VeOBCR_t_RemTimeToBulkSOC_Value: accessed-variable=VeOBCR_t_RemTimeToBulkSOC.Value
            IN_VeOBCR_t_RemTimeToFullSOC_Value: accessed-variable=VeOBCR_t_RemTimeToFullSOC.Value
            IN_VeOHSR_n_IdleSpeed_Target_Value: accessed-variable=VeOHSR_n_IdleSpeed_Target.Value
            IN_VePLTR_pmbar_AmbientAirPrs_Value: accessed-variable=VePLTR_pmbar_AmbientAirPrs.Value
            IN_VePMDR_e_PowerModeRaw_Value: accessed-variable=VePMDR_e_PowerModeRaw.Value
            IN_VePMPR_b_FEDMFlw_FA_Value: accessed-variable=VePMPR_b_FEDMFlw_FA.Value
            IN_VePMPR_b_REDMFlw_FA_Value: accessed-variable=VePMPR_b_REDMFlw_FA.Value
            IN_VePMPR_dV_FEDMFlw_Value: accessed-variable=VePMPR_dV_FEDMFlw.Value
            IN_VePMPR_dV_REDMFlw_Value: accessed-variable=VePMPR_dV_REDMFlw.Value
            IN_VeRGNR_M_EstRegenAchvdAxleTorq_Frnt_Value: accessed-variable=VeRGNR_M_EstRegenAchvdAxleTorq_Frnt.Value
            IN_VeRGNR_M_EstRegenAchvdAxleTorq_Rear_Value: accessed-variable=VeRGNR_M_EstRegenAchvdAxleTorq_Rear.Value
            IN_VeSCCR_b_ESCTrqEnblRq_Allowed_Value: accessed-variable=VeSCCR_b_ESCTrqEnblRq_Allowed.Value
            IN_VeSCPR_b_FOTASchCnflct_Value: accessed-variable=VeSCPR_b_FOTASchCnflct.Value
            IN_VeSRAR_b_CAN_HybFeedback_ECM_Value: accessed-variable=VeSRAR_b_CAN_HybFeedback_ECM.Value
            IN_VeSRAR_b_HCP_Remedial_Stop_Value: accessed-variable=VeSRAR_b_HCP_Remedial_Stop.Value, variation-point={short-label=vpIN_VeSRAR_b_HCP_Remedial_Stop_Value, sw-syscond=1}
            IN_VeSRAR_b_HybPwrtrnRdcdPerfCmnd_Value: accessed-variable=VeSRAR_b_HybPwrtrnRdcdPerfCmnd.Value
            IN_VeSRAR_n_HCPMaxEngRPM_Value: accessed-variable=VeSRAR_n_HCPMaxEngRPM.Value
            IN_VeSRMR_M_ActualAxleTrq_Value: accessed-variable=VeSRMR_M_ActualAxleTrq.Value
            IN_VeSRMR_M_AeCoastTorqDiff_Value: accessed-variable=VeSRMR_M_AeCoastTorqDiff.Value
            IN_VeSRMR_M_EngTrqCmndImmed_Value: accessed-variable=VeSRMR_M_EngTrqCmndImmed.Value, variation-point={short-label=vpIN_VeSRMR_M_EngTrqCmndImmed_Value, sw-syscond=1}
            IN_VeSRMR_M_EngTrqCmndPrdtd_Value: accessed-variable=VeSRMR_M_EngTrqCmndPrdtd.Value, variation-point={short-label=vpIN_VeSRMR_M_EngTrqCmndPrdtd_Value, sw-syscond=1}
            IN_VeSRMR_M_MaxAxleTrqCruise_Value: accessed-variable=VeSRMR_M_MaxAxleTrqCruise.Value
            IN_VeSRMR_M_MinAxleTrqCruise_Value: accessed-variable=VeSRMR_M_MinAxleTrqCruise.Value
            IN_VeSRMR_M_MtrA_TorqCmnd_Value: accessed-variable=VeSRMR_M_MtrA_TorqCmnd.Value
            IN_VeSRMR_M_MtrB_TorqCmnd_Value: accessed-variable=VeSRMR_M_MtrB_TorqCmnd.Value
            IN_VeSRMR_M_RegenBrkAxTorqCapFrnt_Value: accessed-variable=VeSRMR_M_RegenBrkAxTorqCapFrnt.Value
            IN_VeSRMR_M_RegenBrkAxTorqCapRear_Value: accessed-variable=VeSRMR_M_RegenBrkAxTorqCapRear.Value
            IN_VeSRMR_M_SnsdEng_Flt_Value: accessed-variable=VeSRMR_M_SnsdEng_Flt.Value
            IN_VeSRMR_M_SplitFrntTrqReq_Value: accessed-variable=VeSRMR_M_SplitFrntTrqReq.Value
            IN_VeSRMR_M_SplitRearTrqReq_Value: accessed-variable=VeSRMR_M_SplitRearTrqReq.Value
            IN_VeSRMR_Pct_Lv2AccelPdlPos_Value: accessed-variable=VeSRMR_Pct_Lv2AccelPdlPos.Value
            IN_VeSRMR_b_AHH_ModifyAccel_Req_Value: accessed-variable=VeSRMR_b_AHH_ModifyAccel_Req.Value
            IN_VeSRMR_b_AeCoastTorqDiffActv_Value: accessed-variable=VeSRMR_b_AeCoastTorqDiffActv.Value
            IN_VeSRMR_b_HybFeedback_ECM_Value: accessed-variable=VeSRMR_b_HybFeedback_ECM.Value, variation-point={short-label=vpIN_VeSRMR_b_HybFeedback_ECM_Value, sw-syscond=1}
            IN_VeSRMR_b_Lv2AccelPdlPosFlt_Value: accessed-variable=VeSRMR_b_Lv2AccelPdlPosFlt.Value
            IN_VeSRMR_b_Popup_Msg9_Value: accessed-variable=VeSRMR_b_Popup_Msg9.Value
            IN_VeSRMR_b_SnsdTi_notVld_Value: accessed-variable=VeSRMR_b_SnsdTi_notVld.Value
            IN_VeSRMR_b_VehSpdFA_Value: accessed-variable=VeSRMR_b_VehSpdFA.Value
            IN_VeSRMR_b_VehStndStillReq_OPD_Value: accessed-variable=VeSRMR_b_VehStndStillReq_OPD.Value
            IN_VeSRMR_e_AHH_ApplyRelease_Req_Value: accessed-variable=VeSRMR_e_AHH_ApplyRelease_Req.Value
            IN_VeSRMR_e_EPB_Hold_Req_Value: accessed-variable=VeSRMR_e_EPB_Hold_Req.Value
            IN_VeSRMR_e_EngCntrlMode_Value: accessed-variable=VeSRMR_e_EngCntrlMode.Value, variation-point={short-label=vpIN_VeSRMR_e_EngCntrlMode_Value, sw-syscond=1}
            IN_VeSRMR_e_HybCmndEngTorqRespTyp_Value: accessed-variable=VeSRMR_e_HybCmndEngTorqRespTyp.Value, variation-point={short-label=vpIN_VeSRMR_e_HybCmndEngTorqRespTyp_Value, sw-syscond=1}
            IN_VeSRMR_e_MainHighVltCntctrCmd_Value: accessed-variable=VeSRMR_e_MainHighVltCntctrCmd.Value
            IN_VeSRMR_e_MtrA_MdCmnd_Value: accessed-variable=VeSRMR_e_MtrA_MdCmnd.Value
            IN_VeSRMR_e_MtrB_MdCmnd_Value: accessed-variable=VeSRMR_e_MtrB_MdCmnd.Value
            IN_VeSRMR_e_PPawl_Request_Value: accessed-variable=VeSRMR_e_PPawl_Request.Value
            IN_VeSRMR_e_PRNDLReq_Value: accessed-variable=VeSRMR_e_PRNDLReq.Value
            IN_VeSRMR_e_VldtdTransShiftRngSt_Value: accessed-variable=VeSRMR_e_VldtdTransShiftRngSt.Value
            IN_VeSRMR_v_VehSpd_Value: accessed-variable=VeSRMR_v_VehSpd.Value
            IN_VeSSDR_b_DrvNotAllwdTPChckKeepPlugIn_Value: accessed-variable=VeSSDR_b_DrvNotAllwdTPChckKeepPlugIn.Value
            IN_VeSTRR_b_HybCrnkAbrtd_Value: accessed-variable=VeSTRR_b_HybCrnkAbrtd.Value
            IN_VeTAIR_Pct_AGS2_CurrPos_Value: accessed-variable=VeTAIR_Pct_AGS2_CurrPos.Value
            IN_VeTAIR_Pct_AGS_CurrPos_Value: accessed-variable=VeTAIR_Pct_AGS_CurrPos.Value
            IN_VeTAIR_b_AGS2_CurrPosFA_Value: accessed-variable=VeTAIR_b_AGS2_CurrPosFA.Value
            IN_VeTAIR_b_AGS_CurrPosFA_Value: accessed-variable=VeTAIR_b_AGS_CurrPosFA.Value
            IN_VeTAIR_b_HghRfrgtPres_FA_Value: accessed-variable=VeTAIR_b_HghRfrgtPres_FA.Value
            IN_VeTAIR_p_HghRfrgtPres_Value: accessed-variable=VeTAIR_p_HghRfrgtPres.Value
            IN_VeTHMR_e_HV_Bat_CltLvlLo_Value: accessed-variable=VeTHMR_e_HV_Bat_CltLvlLo.Value
            IN_VeTIMR_b_Selector_Sys_Fail_Sts_Value: accessed-variable=VeTIMR_b_Selector_Sys_Fail_Sts.Value
            IN_VeTIMR_e_CustomDrvMdSts_Value: accessed-variable=VeTIMR_e_CustomDrvMdSts.Value
            IN_VeTIMR_e_CustomScreenRqst_Value: accessed-variable=VeTIMR_e_CustomScreenRqst.Value, variation-point={short-label=vpIN_VeTIMR_e_CustomScreenRqst_Value, sw-syscond=1}
            IN_VeTIMR_e_LaunchIntensity_Value: accessed-variable=VeTIMR_e_LaunchIntensity.Value, variation-point={short-label=vpIN_VeTIMR_e_LaunchIntensity_Value, sw-syscond=1}
            IN_VeTIMR_e_RaceModeSts_Value: accessed-variable=VeTIMR_e_RaceModeSts.Value, variation-point={short-label=vpIN_VeTIMR_e_RaceModeSts_Value, sw-syscond=1}
            IN_VeTIMR_e_RaceOptions_Sts_Value: accessed-variable=VeTIMR_e_RaceOptions_Sts.Value, variation-point={short-label=vpIN_VeTIMR_e_RaceOptions_Sts_Value, sw-syscond=1}
            IN_VeTIMR_e_RacePrep_Value: accessed-variable=VeTIMR_e_RacePrep.Value, variation-point={short-label=vpIN_VeTIMR_e_RacePrep_Value, sw-syscond=1}
            IN_VeTISR_b_InputSpeedFA_Value: accessed-variable=VeTISR_b_InputSpeedFA.Value
            IN_VeTISR_n_InputSpeedRaw_Value: accessed-variable=VeTISR_n_InputSpeedRaw.Value
            IN_VeTMDR_e_Arb_TrrnMd_Value: accessed-variable=VeTMDR_e_Arb_TrrnMd.Value, variation-point={short-label=vpIN_VeTMDR_e_Arb_TrrnMd_Value, sw-syscond=1}
            IN_VeTRAR_M_EngReserveTrqCmnd_Value: accessed-variable=VeTRAR_M_EngReserveTrqCmnd.Value
            IN_VeTRAR_M_EngTorqCmndImmed_Value: accessed-variable=VeTRAR_M_EngTorqCmndImmed.Value
            IN_VeTRAR_M_HybCmndEngTorqPrdtd_Value: accessed-variable=VeTRAR_M_HybCmndEngTorqPrdtd.Value
            IN_VeTRAR_b_EngDFCOReq_Value: accessed-variable=VeTRAR_b_EngDFCOReq.Value
            IN_VeTRAR_e_EngCntrlMode_Value: accessed-variable=VeTRAR_e_EngCntrlMode.Value
            IN_VeTRAR_e_HybCmndEngTorqRespTyp_Value: accessed-variable=VeTRAR_e_HybCmndEngTorqRespTyp.Value
            IN_VeTRGR_b_ADAS_Allowed_Value: accessed-variable=VeTRGR_b_ADAS_Allowed.Value
            IN_VeTRGR_b_AutoPark_DAI_Value: accessed-variable=VeTRGR_b_AutoPark_DAI.Value
            IN_VeTRGR_b_CrankEnabled_Value: accessed-variable=VeTRGR_b_CrankEnabled.Value
            IN_VeTRGR_b_GearIndicationSts_Value: accessed-variable=VeTRGR_b_GearIndicationSts.Value
            IN_VeTRGR_b_ParkingFailSts_Value: accessed-variable=VeTRGR_b_ParkingFailSts.Value
            IN_VeTRGR_b_ParkingSts_Value: accessed-variable=VeTRGR_b_ParkingSts.Value
            IN_VeTRGR_b_R_Shift_Block_Value: accessed-variable=VeTRGR_b_R_Shift_Block.Value
            IN_VeTRGR_b_ShifterLocked_Value: accessed-variable=VeTRGR_b_ShifterLocked.Value
            IN_VeTRGR_b_TransmissionFailSts_Value: accessed-variable=VeTRGR_b_TransmissionFailSts.Value
            IN_VeTRGR_e_AutoPosCorrMdReq_Value: accessed-variable=VeTRGR_e_AutoPosCorrMdReq.Value
            IN_VeTRGR_e_CurrentGear_Value: accessed-variable=VeTRGR_e_CurrentGear.Value
            IN_VeTRGR_e_CurrentGrForDisp_Value: accessed-variable=VeTRGR_e_CurrentGrForDisp.Value
            IN_VeTRGR_e_SecureIdleSts_Value: accessed-variable=VeTRGR_e_SecureIdleSts.Value
            IN_VeTRGR_e_SecureIdle_HMI_Value: accessed-variable=VeTRGR_e_SecureIdle_HMI.Value
            IN_VeTRGR_e_TargetGear_Value: accessed-variable=VeTRGR_e_TargetGear.Value
            IN_VeTRNR_b_InertiaTrqActv_Value: accessed-variable=VeTRNR_b_InertiaTrqActv.Value, variation-point={short-label=vpIN_VeTRNR_b_InertiaTrqActv_Value, sw-syscond=1}
            IN_VeTRNR_b_PwrTrnIdlSpdActvSts_Value: accessed-variable=VeTRNR_b_PwrTrnIdlSpdActvSts.Value
            IN_VeTTQR_M_LoadFrontOptExp_Value: accessed-variable=VeTTQR_M_LoadFrontOptExp.Value, variation-point={short-label=vpIN_VeTTQR_M_LoadFrontOptExp_Value, sw-syscond=1}
            IN_VeTTQR_M_LoadFrontOptShaped_Value: accessed-variable=VeTTQR_M_LoadFrontOptShaped.Value, variation-point={short-label=vpIN_VeTTQR_M_LoadFrontOptShaped_Value, sw-syscond=1}
            IN_VeTTQR_M_LoadFrontOpt_xShaping_Value: accessed-variable=VeTTQR_M_LoadFrontOpt_xShaping.Value, variation-point={short-label=vpIN_VeTTQR_M_LoadFrontOpt_xShaping_Value, sw-syscond=1}
            IN_VeTTQR_M_LoadTorqFront_Max_Value: accessed-variable=VeTTQR_M_LoadTorqFront_Max.Value
            IN_VeTTQR_M_LoadTorqFront_Min_Value: accessed-variable=VeTTQR_M_LoadTorqFront_Min.Value, variation-point={short-label=vpIN_VeTTQR_M_LoadTorqFront_Min_Value, sw-syscond=1}
            IN_VeTTQR_M_LoadTorqFront_Opt_Value: accessed-variable=VeTTQR_M_LoadTorqFront_Opt.Value, variation-point={short-label=vpIN_VeTTQR_M_LoadTorqFront_Opt_Value, sw-syscond=1}
            IN_VeTTQR_M_SumTrqAct_SEM_Value: accessed-variable=VeTTQR_M_SumTrqAct_SEM.Value, variation-point={short-label=vpIN_VeTTQR_M_SumTrqAct_SEM_Value, sw-syscond=1}
            IN_VeTTQR_M_SumTrqMinPwrTrn_Value: accessed-variable=VeTTQR_M_SumTrqMinPwrTrn.Value
            IN_VeTTQR_M_SumTrqStatic_Value: accessed-variable=VeTTQR_M_SumTrqStatic.Value
            IN_VeVSMR_M_VirtEngTorq_Value: accessed-variable=VeVSMR_M_VirtEngTorq.Value, variation-point={short-label=vpIN_VeVSMR_M_VirtEngTorq_Value, sw-syscond=1}
            IN_VeVSMR_e_VirtShftTypeGrp_Value: accessed-variable=VeVSMR_e_VirtShftTypeGrp.Value, variation-point={short-label=vpIN_VeVSMR_e_VirtShftTypeGrp_Value, sw-syscond=1}
            IN_VeVSMR_n_VirtEngSpd_Value: accessed-variable=VeVSMR_n_VirtEngSpd.Value, variation-point={short-label=vpIN_VeVSMR_n_VirtEngSpd_Value, sw-syscond=1}
            IN_VeVTLR_I_MaxCurrAlwd_IDCM_Value: accessed-variable=VeVTLR_I_MaxCurrAlwd_IDCM.Value
            IN_VeVTLR_I_MaxCurrAlwd_PPIM_Value: accessed-variable=VeVTLR_I_MaxCurrAlwd_PPIM.Value
            IN_VeVTLR_b_ACFreqCmd_Value: accessed-variable=VeVTLR_b_ACFreqCmd.Value
            IN_VeVTLR_e_PPIM_MdRq_Value: accessed-variable=VeVTLR_e_PPIM_MdRq.Value
            IN_VeWTAR_M_IntndedAxleTrq_Shpd_Value: accessed-variable=VeWTAR_M_IntndedAxleTrq_Shpd.Value
            IN_VeWTAR_M_IntndedAxleTrq_xShpng_Value: accessed-variable=VeWTAR_M_IntndedAxleTrq_xShpng.Value
        data-send-points:
          40 x access:
            OUT_VeST2B_h_COMTX_AXLE_TORQUE_FD_1_FD3_Pkt_COMTX_AXLE_TORQUE_FD_1_FD3_Pkt: accessed-variable=VeST2B_h_COMTX_AXLE_TORQUE_FD_1_FD3_Pkt.COMTX_AXLE_TORQUE_FD_1_FD3_Pkt
            OUT_VeST2B_h_COMTX_DRIVETRAIN_FD_3_FD3_Pkt_COMTX_DRIVETRAIN_FD_3_FD3_Pkt: accessed-variable=VeST2B_h_COMTX_DRIVETRAIN_FD_3_FD3_Pkt.COMTX_DRIVETRAIN_FD_3_FD3_Pkt
            OUT_VeST2B_h_COMTX_ENGINE_SIMULATOR1_FD3_Pkt_COMTX_ENGINE_SIMULATOR1_FD3_Pkt: accessed-variable=VeST2B_h_COMTX_ENGINE_SIMULATOR1_FD3_Pkt.COMTX_ENGINE_SIMULATOR1_FD3_Pkt
            OUT_VeST2B_h_COMTX_HYBRID_DISPLAY_FD3_Pkt_COMTX_HYBRID_DISPLAY_FD3_Pkt: accessed-variable=VeST2B_h_COMTX_HYBRID_DISPLAY_FD3_Pkt.COMTX_HYBRID_DISPLAY_FD3_Pkt
            OUT_VeST2B_h_COMTX_HYBRID_POWERTRAIN1_FD3_Pkt_COMTX_HYBRID_POWERTRAIN1_FD3_Pkt: accessed-variable=VeST2B_h_COMTX_HYBRID_POWERTRAIN1_FD3_Pkt.COMTX_HYBRID_POWERTRAIN1_FD3_Pkt
            OUT_VeST2B_h_COMTX_HYBRID_POWERTRAIN2_FD3_Pkt_COMTX_HYBRID_POWERTRAIN2_FD3_Pkt: accessed-variable=VeST2B_h_COMTX_HYBRID_POWERTRAIN2_FD3_Pkt.COMTX_HYBRID_POWERTRAIN2_FD3_Pkt
            OUT_VeST2B_h_COMTX_HYBRID_POWERTRAIN4_FD3_Pkt_COMTX_HYBRID_POWERTRAIN4_FD3_Pkt: accessed-variable=VeST2B_h_COMTX_HYBRID_POWERTRAIN4_FD3_Pkt.COMTX_HYBRID_POWERTRAIN4_FD3_Pkt
            OUT_VeST2B_h_COMTX_HYBRID_POWERTRAIN5_FD3_Pkt_COMTX_HYBRID_POWERTRAIN5_FD3_Pkt: accessed-variable=VeST2B_h_COMTX_HYBRID_POWERTRAIN5_FD3_Pkt.COMTX_HYBRID_POWERTRAIN5_FD3_Pkt
            OUT_VeST2B_h_COMTX_PT_SYSTEM_FD_1_FD3_Pkt_COMTX_PT_SYSTEM_FD_1_FD3_Pkt: accessed-variable=VeST2B_h_COMTX_PT_SYSTEM_FD_1_FD3_Pkt.COMTX_PT_SYSTEM_FD_1_FD3_Pkt
            OUT_VeST2B_h_COMTX_PT_TORQUE_FD_1_FD3_Pkt_COMTX_PT_TORQUE_FD_1_FD3_Pkt: accessed-variable=VeST2B_h_COMTX_PT_TORQUE_FD_1_FD3_Pkt.COMTX_PT_TORQUE_FD_1_FD3_Pkt
            OUT_VeST2B_h_COMTX_TRANSM_FD_1_FD3_Pkt_COMTX_TRANSM_FD_1_FD3_Pkt: accessed-variable=VeST2B_h_COMTX_TRANSM_FD_1_FD3_Pkt.COMTX_TRANSM_FD_1_FD3_Pkt
            OUT_VeST2B_h_COMTX_TRANSM_FD_2_FD3_Pkt_COMTX_TRANSM_FD_2_FD3_Pkt: accessed-variable=VeST2B_h_COMTX_TRANSM_FD_2_FD3_Pkt.COMTX_TRANSM_FD_2_FD3_Pkt
            OUT_VeST2B_h_COMTX_VDCM_HMI_FD3_Pkt_COMTX_VDCM_HMI_FD3_Pkt: accessed-variable=VeST2B_h_COMTX_VDCM_HMI_FD3_Pkt.COMTX_VDCM_HMI_FD3_Pkt
            OUT_VeST2B_h_COMTX_EVCU_ISO15118_STATUS1_FD11_Pkt_COMTX_EVCU_ISO15118_STATUS1_FD11_Pkt: accessed-variable=VeST2B_h_COMTX_EVCU_ISO15118_STATUS1_FD11_Pkt.COMTX_EVCU_ISO15118_STATUS1_FD11_Pkt
            OUT_VeST2B_h_COMTX_HYBRID_CHARGING_COMMAND_FD11_Pkt_COMTX_HYBRID_CHARGING_COMMAND_FD11_Pkt: accessed-variable=VeST2B_h_COMTX_HYBRID_CHARGING_COMMAND_FD11_Pkt.COMTX_HYBRID_CHARGING_COMMAND_FD11_Pkt
            OUT_VeST2B_h_COMTX_HYBRID_CHARGING_STATUS_FD11_Pkt_COMTX_HYBRID_CHARGING_STATUS_FD11_Pkt: accessed-variable=VeST2B_h_COMTX_HYBRID_CHARGING_STATUS_FD11_Pkt.COMTX_HYBRID_CHARGING_STATUS_FD11_Pkt
            OUT_VeST2B_h_COMTX_HYBRID_POWERTRAIN1_FD11_Pkt_COMTX_HYBRID_POWERTRAIN1_FD11_Pkt: accessed-variable=VeST2B_h_COMTX_HYBRID_POWERTRAIN1_FD11_Pkt.COMTX_HYBRID_POWERTRAIN1_FD11_Pkt
            OUT_VeST2B_h_COMTX_PT_ENERGY_FD_1_FD11_Pkt_COMTX_PT_ENERGY_FD_1_FD11_Pkt: accessed-variable=VeST2B_h_COMTX_PT_ENERGY_FD_1_FD11_Pkt.COMTX_PT_ENERGY_FD_1_FD11_Pkt
            OUT_VeST2B_h_COMTX_RPF_FD_3_FD11_Pkt_COMTX_RPF_FD_3_FD11_Pkt: accessed-variable=VeST2B_h_COMTX_RPF_FD_3_FD11_Pkt.COMTX_RPF_FD_3_FD11_Pkt
            OUT_VeST2B_h_COMTX_VDCM_OBCM2_FD11_Pkt_COMTX_VDCM_OBCM2_FD11_Pkt: accessed-variable=VeST2B_h_COMTX_VDCM_OBCM2_FD11_Pkt.COMTX_VDCM_OBCM2_FD11_Pkt
            OUT_VeST2B_h_COMTX_AXLE_TORQUE_FD_1_FD14_Pkt_COMTX_AXLE_TORQUE_FD_1_FD14_Pkt: accessed-variable=VeST2B_h_COMTX_AXLE_TORQUE_FD_1_FD14_Pkt.COMTX_AXLE_TORQUE_FD_1_FD14_Pkt
            OUT_VeST2B_h_COMTX_PT_SYSTEM_FD_1_FD14_Pkt_COMTX_PT_SYSTEM_FD_1_FD14_Pkt: accessed-variable=VeST2B_h_COMTX_PT_SYSTEM_FD_1_FD14_Pkt.COMTX_PT_SYSTEM_FD_1_FD14_Pkt
            OUT_VeST2B_h_COMTX_PT_TORQUE_FD_1_FD14_Pkt_COMTX_PT_TORQUE_FD_1_FD14_Pkt: accessed-variable=VeST2B_h_COMTX_PT_TORQUE_FD_1_FD14_Pkt.COMTX_PT_TORQUE_FD_1_FD14_Pkt
            OUT_VeST2B_h_COMTX_HYBRID_POWERTRAIN1_FD16_Pkt_COMTX_HYBRID_POWERTRAIN1_FD16_Pkt: accessed-variable=VeST2B_h_COMTX_HYBRID_POWERTRAIN1_FD16_Pkt.COMTX_HYBRID_POWERTRAIN1_FD16_Pkt
            OUT_VeST2B_h_COMTX_HYBRID_POWERTRAIN2_FD16_Pkt_COMTX_HYBRID_POWERTRAIN2_FD16_Pkt: accessed-variable=VeST2B_h_COMTX_HYBRID_POWERTRAIN2_FD16_Pkt.COMTX_HYBRID_POWERTRAIN2_FD16_Pkt
            OUT_VeST2B_h_COMTX_HYBRID_POWERTRAIN5_FD16_Pkt_COMTX_HYBRID_POWERTRAIN5_FD16_Pkt: accessed-variable=VeST2B_h_COMTX_HYBRID_POWERTRAIN5_FD16_Pkt.COMTX_HYBRID_POWERTRAIN5_FD16_Pkt
            OUT_VeST2B_h_COMTX_INVTARGET_PROPULSION1_FD16_Pkt_COMTX_INVTARGET_PROPULSION1_FD16_Pkt: accessed-variable=VeST2B_h_COMTX_INVTARGET_PROPULSION1_FD16_Pkt.COMTX_INVTARGET_PROPULSION1_FD16_Pkt
            OUT_VeST2B_h_COMTX_INVTARGET_PROPULSION2_FD16_Pkt_COMTX_INVTARGET_PROPULSION2_FD16_Pkt: accessed-variable=VeST2B_h_COMTX_INVTARGET_PROPULSION2_FD16_Pkt.COMTX_INVTARGET_PROPULSION2_FD16_Pkt
            OUT_VeST2B_h_COMTX_PT_SYSTEM_FD_1_FD16_Pkt_COMTX_PT_SYSTEM_FD_1_FD16_Pkt: accessed-variable=VeST2B_h_COMTX_PT_SYSTEM_FD_1_FD16_Pkt.COMTX_PT_SYSTEM_FD_1_FD16_Pkt
            OUT_VeST2B_h_COMTX_PT_TORQUE_FD_1_FD16_Pkt_COMTX_PT_TORQUE_FD_1_FD16_Pkt: accessed-variable=VeST2B_h_COMTX_PT_TORQUE_FD_1_FD16_Pkt.COMTX_PT_TORQUE_FD_1_FD16_Pkt
            OUT_VeST2B_h_COMTX_HYBRID_CHARGING_COMMAND_FD5_Pkt_COMTX_HYBRID_CHARGING_COMMAND_FD5_Pkt: accessed-variable=VeST2B_h_COMTX_HYBRID_CHARGING_COMMAND_FD5_Pkt.COMTX_HYBRID_CHARGING_COMMAND_FD5_Pkt
            OUT_VeST2B_h_COMTX_HYBRID_CHARGING_STATUS_FD5_Pkt_COMTX_HYBRID_CHARGING_STATUS_FD5_Pkt: accessed-variable=VeST2B_h_COMTX_HYBRID_CHARGING_STATUS_FD5_Pkt.COMTX_HYBRID_CHARGING_STATUS_FD5_Pkt
            OUT_VeST2B_h_COMTX_HYBRID_FD_LHOM_FD5_Pkt_COMTX_HYBRID_FD_LHOM_FD5_Pkt: accessed-variable=VeST2B_h_COMTX_HYBRID_FD_LHOM_FD5_Pkt.COMTX_HYBRID_FD_LHOM_FD5_Pkt
            OUT_VeST2B_h_COMTX_HYBRID_POWERTRAIN1_FD5_Pkt_COMTX_HYBRID_POWERTRAIN1_FD5_Pkt: accessed-variable=VeST2B_h_COMTX_HYBRID_POWERTRAIN1_FD5_Pkt.COMTX_HYBRID_POWERTRAIN1_FD5_Pkt
            OUT_VeST2B_h_COMTX_HYBRID_POWERTRAIN5_FD5_Pkt_COMTX_HYBRID_POWERTRAIN5_FD5_Pkt: accessed-variable=VeST2B_h_COMTX_HYBRID_POWERTRAIN5_FD5_Pkt.COMTX_HYBRID_POWERTRAIN5_FD5_Pkt
            OUT_VeST2B_h_COMTX_INVTARGET_PROPULSION1_FD5_Pkt_COMTX_INVTARGET_PROPULSION1_FD5_Pkt: accessed-variable=VeST2B_h_COMTX_INVTARGET_PROPULSION1_FD5_Pkt.COMTX_INVTARGET_PROPULSION1_FD5_Pkt
            OUT_VeST2B_h_COMTX_INVTARGET_PROPULSION2_FD5_Pkt_COMTX_INVTARGET_PROPULSION2_FD5_Pkt: accessed-variable=VeST2B_h_COMTX_INVTARGET_PROPULSION2_FD5_Pkt.COMTX_INVTARGET_PROPULSION2_FD5_Pkt
            OUT_VeST2B_h_COMTX_PT_ENERGY_FD_1_FD5_Pkt_COMTX_PT_ENERGY_FD_1_FD5_Pkt: accessed-variable=VeST2B_h_COMTX_PT_ENERGY_FD_1_FD5_Pkt.COMTX_PT_ENERGY_FD_1_FD5_Pkt
            OUT_VeST2B_h_COMTX_PT_SYSTEM_FD_1_FD5_Pkt_COMTX_PT_SYSTEM_FD_1_FD5_Pkt: accessed-variable=VeST2B_h_COMTX_PT_SYSTEM_FD_1_FD5_Pkt.COMTX_PT_SYSTEM_FD_1_FD5_Pkt
            OUT_VeST2B_h_COMTX_VDCM_OBCM2_FD5_Pkt_COMTX_VDCM_OBCM2_FD5_Pkt: accessed-variable=VeST2B_h_COMTX_VDCM_OBCM2_FD5_Pkt.COMTX_VDCM_OBCM2_FD5_Pkt
        sync call SC_ST2B_FUNC_FastTEF_StartCheckpoint_CheckpointReached: operation=ST2B_FUNC_FastTEF_StartCheckpoint.CheckpointReached, timeout=1E-06
        sync call SC_ST2B_FUNC_FastTEF_StopCheckpoint_CheckpointReached: operation=ST2B_FUNC_FastTEF_StopCheckpoint.CheckpointReached, timeout=1E-06
      122 x variation point proxy, all with category=CONDITION:
        VrntST2B_DRIVETRAINFD3FD3_VeDMIReESaveLEDOn: condition-access=0
        VrntST2B_DRIVETRAINFD3FD3_VeDMIReEcoLEDOn: condition-access=0
        VrntST2B_DRIVETRAINFD3FD3_VeDMIReEcoLEDOn1: condition-access=1
        VrntST2B_DRIVETRAINFD3FD3_VeDMIReElectricPlusLEDOn: condition-access=0
        VrntST2B_ENGINESIMULATOR1FD3_VeHMIReeBoostSts: condition-access=1
        VrntST2B_ENGINESIMULATOR1FD3_VeMSPRnMtrASpd: condition-access=1
        VrntST2B_ENGINESIMULATOR1FD3_VeMSPRnMtrBSpd: condition-access=1
        VrntST2B_ENGINESIMULATOR1FD3_VeMTIRMMtrATorqAchieved: condition-access=1
        VrntST2B_ENGINESIMULATOR1FD3_VeMTIRMMtrBTorqAchieved1: condition-access=1
        VrntST2B_ENGINESIMULATOR1FD3_VeSRMRMMtrATorqCmnd: condition-access=1
        VrntST2B_ENGINESIMULATOR1FD3_VeSRMRMMtrBTorqCmnd: condition-access=1
        VrntST2B_ENGINESIMULATOR1FD3_VeTIMReRaceModeSts: condition-access=1
        VrntST2B_ENGINESIMULATOR1FD3_VeTIMReRaceOptionsSts: condition-access=1
        VrntST2B_ENGINESIMULATOR1FD3_VeVSMRMVirtEngTorq: condition-access=1
        VrntST2B_ENGINESIMULATOR1FD3_VeVSMReVirtShftTypeGrp: condition-access=1
        VrntST2B_ENGINESIMULATOR1FD3_VeVSMRnVirtEngSpd: condition-access=1
        VrntST2B_HYBRIDCHARGINGCOMMANDFD11_VeOBCRUMaxAllowableBattVolt1: condition-access=0
        VrntST2B_HYBRIDCHARGINGCOMMANDFD11_VeOBCRUMinAllowableBattVolt1: condition-access=0
        VrntST2B_HYBRIDCHARGINGCOMMANDFD5_VeOBCRUMaxAllowableBattVolt1: condition-access=0
        VrntST2B_HYBRIDCHARGINGCOMMANDFD5_VeOBCRUMinAllowableBattVolt1: condition-access=0
        VrntST2B_HYBRIDDISPLAYFD3_VeHMIRPBatPwrUsageDisp1: condition-access=0
        VrntST2B_HYBRIDDISPLAYFD3_VeHMIRbBatPwrUsageDispV1: condition-access=0
        VrntST2B_HYBRIDDISPLAYFD3_VeHMIRbPopupMsg1: condition-access=1
        VrntST2B_HYBRIDDISPLAYFD3_VeSRARbPopupMsg1: condition-access=0
        VrntST2B_HYBRIDDISPLAYFD3_VeTIMReRacePrep: condition-access=1
        VrntST2B_HYBRIDFDLHOMFD5_VeHSERnInputSpeedProfile: condition-access=1
        VrntST2B_HYBRIDFDLHOMFD5_VeICSRbAdvancePrepForIdle: condition-access=1
        VrntST2B_HYBRIDFDLHOMFD5_VeSRMRMEngTrqCmndImmed: condition-access=1
        VrntST2B_HYBRIDFDLHOMFD5_VeSRMRMEngTrqCmndPrdtd: condition-access=1
        VrntST2B_HYBRIDFDLHOMFD5_VeSRMRMSnsdEngFlt: condition-access=1
        VrntST2B_HYBRIDFDLHOMFD5_VeSRMRbHybFeedbackECM: condition-access=1
        VrntST2B_HYBRIDFDLHOMFD5_VeSRMRbSnsdTinotVld: condition-access=1
        VrntST2B_HYBRIDFDLHOMFD5_VeSRMReEngCntrlMode: condition-access=1
        VrntST2B_HYBRIDFDLHOMFD5_VeSRMReHybCmndEngTorqRespTyp: condition-access=1
        VrntST2B_HYBRIDFDLHOMFD5_VeTISRnInputSpeedRaw: condition-access=1
        VrntST2B_HYBRIDFDLHOMFD5_VeTRARMEngReserveTrqCmnd: condition-access=1
        VrntST2B_HYBRIDFDLHOMFD5_VeTRNRbPwrTrnIdlSpdActvSts: condition-access=1
        VrntST2B_HYBRIDPOWERTRAIN1FD16_VeSRARbHCPRemedialStop: condition-access=1
        VrntST2B_HYBRIDPOWERTRAIN1FD16_VeSTRRbRemedialStop: condition-access=0
        VrntST2B_HYBRIDPOWERTRAIN1FD3_VeHMIReeBoostWarn: condition-access=1
        VrntST2B_HYBRIDPOWERTRAIN1FD3_VeSRARbHCPRemedialStop: condition-access=1
        VrntST2B_HYBRIDPOWERTRAIN1FD3_VeSTRRbRemedialStop: condition-access=0
        VrntST2B_HYBRIDPOWERTRAIN1FD5_VeSRARbHCPRemedialStop: condition-access=1
        VrntST2B_HYBRIDPOWERTRAIN1FD5_VeSTRRbRemedialStop: condition-access=0
        VrntST2B_HYBRIDPOWERTRAIN2FD3_VeMTIRMMtrBTorqAchieved: condition-access=1
        VrntST2B_HYBRIDPOWERTRAIN2FD3_VeMTIRMMtrCTorqAchieved: condition-access=0
        VrntST2B_HYBRIDPOWERTRAIN4FD3_VeTMDReArbTrrnMd: condition-access=1
        VrntST2B_HYBRIDPOWERTRAIN4FD3_VeTMDReCmbndDrvMd: condition-access=1
        VrntST2B_HYBRIDPOWERTRAIN5FD3_VeHMIRPMtrAPwrUsageDisp: condition-access=1
        VrntST2B_HYBRIDPOWERTRAIN5FD3_VeHMIRPMtrAPwrUsageDispV: condition-access=1
        VrntST2B_HYBRIDPOWERTRAIN5FD3_VeTIMReLaunchIntensity: condition-access=1
        VrntST2B_INVTARGETPROPULSION1FD16_VeHTDRMMtrAAEMDNegTrqOffst: condition-access=0
        VrntST2B_INVTARGETPROPULSION1FD16_VeHTDRMMtrAAEMDNegTrqOffst1: condition-access=1
        VrntST2B_INVTARGETPROPULSION1FD16_VeHTDRMMtrAAEMDPosTrqOffst: condition-access=0
        VrntST2B_INVTARGETPROPULSION1FD16_VeHTDRMMtrAAEMDPosTrqOffst1: condition-access=1
        VrntST2B_INVTARGETPROPULSION1FD16_VeHTDRMMtrATorqCmnd: condition-access=0
        VrntST2B_INVTARGETPROPULSION1FD16_VeHTDRMMtrCAEMDNegTrqOffst: condition-access=0
        VrntST2B_INVTARGETPROPULSION1FD16_VeHTDRMMtrCAEMDPosTrqOffst: condition-access=0
        VrntST2B_INVTARGETPROPULSION1FD16_VeHTDRbMtrAZeroTrqRqst: condition-access=0
        VrntST2B_INVTARGETPROPULSION1FD16_VeHTDRbMtrAZeroTrqRqst1: condition-access=1
        VrntST2B_INVTARGETPROPULSION1FD16_VeHTDRbMtrCZeroTrqRqst: condition-access=0
        VrntST2B_INVTARGETPROPULSION1FD16_VeHTDReMtrAMdCmnd: condition-access=0
        VrntST2B_INVTARGETPROPULSION1FD16_VeHTDRnMtrASpdCmnd: condition-access=0
        VrntST2B_INVTARGETPROPULSION1FD16_VeHTDRnMtrASpdCmnd1: condition-access=1
        VrntST2B_INVTARGETPROPULSION1FD16_VeHTDRnMtrCSpdCmnd: condition-access=0
        VrntST2B_INVTARGETPROPULSION1FD16_VeHTDRsclMtrAAEMDPGainScl: condition-access=0
        VrntST2B_INVTARGETPROPULSION1FD16_VeHTDRsclMtrAAEMDPGainScl1: condition-access=1
        VrntST2B_INVTARGETPROPULSION1FD16_VeHTDRsclMtrCAEMDPGainScl: condition-access=0
        VrntST2B_INVTARGETPROPULSION1FD5_VeHTDRMMtrAAEMDNegTrqOffst: condition-access=0
        VrntST2B_INVTARGETPROPULSION1FD5_VeHTDRMMtrAAEMDNegTrqOffst1: condition-access=1
        VrntST2B_INVTARGETPROPULSION1FD5_VeHTDRMMtrAAEMDPosTrqOffst: condition-access=0
        VrntST2B_INVTARGETPROPULSION1FD5_VeHTDRMMtrAAEMDPosTrqOffst1: condition-access=1
        VrntST2B_INVTARGETPROPULSION1FD5_VeHTDRMMtrATorqCmnd: condition-access=0
        VrntST2B_INVTARGETPROPULSION1FD5_VeHTDRMMtrCAEMDNegTrqOffst: condition-access=0
        VrntST2B_INVTARGETPROPULSION1FD5_VeHTDRMMtrCAEMDPosTrqOffst: condition-access=0
        VrntST2B_INVTARGETPROPULSION1FD5_VeHTDRbMtrAZeroTrqRqst: condition-access=0
        VrntST2B_INVTARGETPROPULSION1FD5_VeHTDRbMtrAZeroTrqRqst1: condition-access=1
        VrntST2B_INVTARGETPROPULSION1FD5_VeHTDRbMtrCZeroTrqRqst: condition-access=0
        VrntST2B_INVTARGETPROPULSION1FD5_VeHTDReMtrAMdCmnd: condition-access=0
        VrntST2B_INVTARGETPROPULSION1FD5_VeHTDRnMtrASpdCmnd: condition-access=0
        VrntST2B_INVTARGETPROPULSION1FD5_VeHTDRnMtrASpdCmnd1: condition-access=1
        VrntST2B_INVTARGETPROPULSION1FD5_VeHTDRnMtrCSpdCmnd: condition-access=0
        VrntST2B_INVTARGETPROPULSION1FD5_VeHTDRsclMtrAAEMDPGainScl: condition-access=0
        VrntST2B_INVTARGETPROPULSION1FD5_VeHTDRsclMtrAAEMDPGainScl1: condition-access=1
        VrntST2B_INVTARGETPROPULSION1FD5_VeHTDRsclMtrCAEMDPGainScl: condition-access=0
        VrntST2B_INVTARGETPROPULSION2FD16_VePMPRdVGenFlw: condition-access=0
        VrntST2B_INVTARGETPROPULSION2FD5_VePMPRdVGenFlw: condition-access=0
        VrntST2B_PTSYSTEMFD1FD14_VeCSVReTHARespEVCU2: condition-access=0
        VrntST2B_PTSYSTEMFD1FD14_VeCSVReTRSCRespEVCU2: condition-access=0
        VrntST2B_PTSYSTEMFD1FD16_VeCSVRnWhlSpdLHR: condition-access=1
        VrntST2B_PTSYSTEMFD1FD16_VeCSVRnWhlSpdRHR: condition-access=1
        VrntST2B_PTSYSTEMFD1FD16_VeESSRbHCPFuelDisable: condition-access=0
        VrntST2B_PTSYSTEMFD1FD16_VeESSRbHybProducingTorque: condition-access=0
        VrntST2B_PTSYSTEMFD1FD16_VeESSRbOptimdEngOnOffCmd: condition-access=0
        VrntST2B_PTSYSTEMFD1FD16_VeESSReOptimdEngStrtStpType: condition-access=0
        VrntST2B_PTSYSTEMFD1FD16_VeESSReOptimdStrtReqdActr: condition-access=0
        VrntST2B_PTSYSTEMFD1FD16_VeTRNRbInertiaTrqActv: condition-access=1
        VrntST2B_PTSYSTEMFD1FD3_VeCSVReTHARespEVCU2: condition-access=0
        VrntST2B_PTSYSTEMFD1FD3_VeTIMReCustomDrvMdSts: condition-access=1
        VrntST2B_PTSYSTEMFD1FD3_VeTIMReCustomScreenRqst: condition-access=1
        VrntST2B_PTSYSTEMFD1FD5_VeESSRbHCPFuelDisable: condition-access=0
        VrntST2B_PTSYSTEMFD1FD5_VeESSRbHybProducingTorque: condition-access=0
        VrntST2B_PTSYSTEMFD1FD5_VeESSRbOptimdEngOnOffCmd: condition-access=0
        VrntST2B_PTSYSTEMFD1FD5_VeESSReOptimdEngStrtStpType: condition-access=0
        VrntST2B_PTSYSTEMFD1FD5_VeESSReOptimdStrtReqdActr: condition-access=0
        VrntST2B_PTTORQUEFD1FD16_VeTTQRMLoadFrontOptShaped: condition-access=1
        VrntST2B_PTTORQUEFD1FD16_VeTTQRMLoadFrontOptxShaping: condition-access=1
        VrntST2B_PTTORQUEFD1FD16_VeTTQRMLoadTorqFrontMax: condition-access=1
        VrntST2B_PTTORQUEFD1FD16_VeTTQRMLoadTorqFrontMin: condition-access=1
        VrntST2B_PTTORQUEFD1FD16_VeTTQRMLoadTorqFrontOpt: condition-access=1
        VrntST2B_PTTORQUEFD1FD16_VeTTQRMSumTrqActSEM: condition-access=1
        VrntST2B_PTTORQUEFD1FD16_VeTTQRMSumTrqStatic: condition-access=1
        VrntST2B_PTTORQUEFD1FD3_VeTTQRMLoadFrontOptExp: condition-access=1
        VrntST2B_RPFFD3FD11_VeVTHRPV2HEVMaxPwrLim: condition-access=0
        VrntST2B_VDCMOBCM2FD11_VeCHDRbChrgCrntDvatonErr: condition-access=0
        VrntST2B_VDCMOBCM2FD11_VeCHDRtEstChrgTimemin: condition-access=0
        VrntST2B_VDCMOBCM2FD11_VeCHDRtMaxChrgTimemin: condition-access=0
        VrntST2B_VDCMOBCM2FD11_VeCHDRtMaxChrgTimesec: condition-access=0
        VrntST2B_VDCMOBCM2FD5_VeCHDRbChrgCrntDvatonErr: condition-access=0
        VrntST2B_VDCMOBCM2FD5_VeCHDRtEstChrgTimemin: condition-access=0
        VrntST2B_VDCMOBCM2FD5_VeCHDRtMaxChrgTimemin: condition-access=0
        VrntST2B_VDCMOBCM2FD5_VeCHDRtMaxChrgTimesec: condition-access=0
